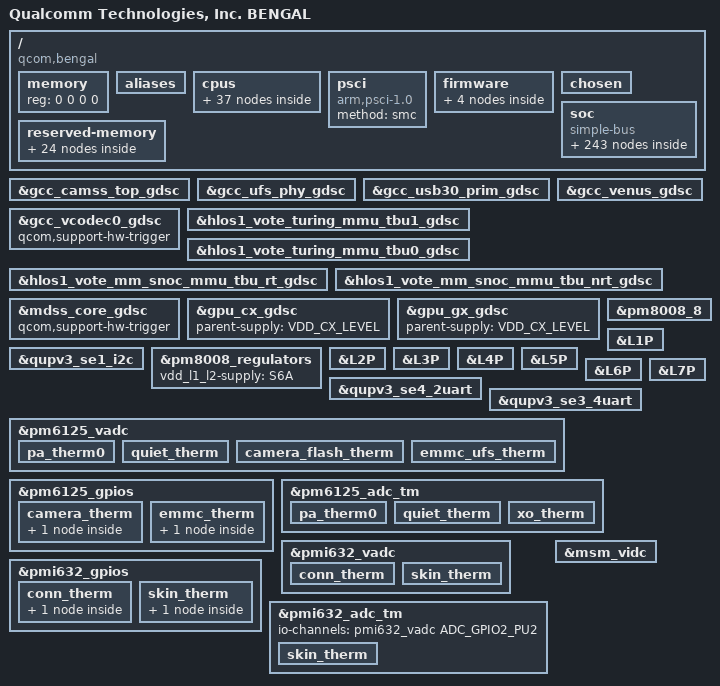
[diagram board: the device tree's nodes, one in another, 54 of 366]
#include <dt-bindings/interrupt-controller/arm-gic.h>
#include <dt-bindings/clock/qcom,rpmcc.h>
#include <dt-bindings/clock/qcom,dispcc-bengal.h>
#include <dt-bindings/clock/qcom,gcc-bengal.h>
#include <dt-bindings/clock/qcom,gpucc-bengal.h>
#include <dt-bindings/spmi/spmi.h>
#include <dt-bindings/regulator/qcom,rpmh-regulator-levels.h>
#include <dt-bindings/msm/msm-bus-ids.h>

#define MHZ_TO_MBPS(mhz, w) ((mhz * 1000000 * w) / (1024 * 1024))
#define BW_OPP_ENTRY(mhz, w) opp-mhz {opp-hz = /bits/ 64 <MHZ_TO_MBPS(mhz, w)>;}

#define BW_OPP_ENTRY_DDR(mhz, w, ddrtype) opp-mhz {\
				opp-hz = /bits/ 64 <MHZ_TO_MBPS(mhz, w)>;\
				opp-supported-hw = <ddrtype>;}

#define DDR_TYPE_LPDDR3		5
#define DDR_TYPE_LPDDR4X	7

/ {
	model = "Qualcomm Technologies, Inc. BENGAL";
	compatible = "qcom,bengal";
	qcom,msm-id = <417 0x10000>, <444 0x10000>;
	interrupt-parent = <&wakegic>;

	#address-cells = <2>;
	#size-cells = <2>;
	memory { device_type = "memory"; reg = <0 0 0 0>; };

	aliases {
		sdhc1 = &sdhc_1; /* SDC1 eMMC slot */
		sdhc2 = &sdhc_2; /* SDC2 SD Card slot */
		swr0 = &swr0;
		swr1 = &swr1;
		ufshc1 = &ufshc_mem; /* Embedded UFS slot */
	};

	cpus {
		#address-cells = <2>;
		#size-cells = <0>;

		CPU0: cpu@0 {
			device_type = "cpu";
			compatible = "arm,armv8";
			reg = <0x0 0x0>;
			capacity-dmips-mhz = <1024>;
			dynamic-power-coefficient = <100>;
			enable-method = "psci";
			d-cache-size = <0x8000>;
			i-cache-size = <0x8000>;
			next-level-cache = <&L2_0>;
			qcom,freq-domain = <&cpufreq_hw 0 7>;
			qcom,lmh-dcvs = <&lmh_dcvs0>;
			#cooling-cells = <2>;
			L2_0: l2-cache {
				compatible = "arm,arch-cache";
				cache-level = <2>;
			};

			L1_I_0: l1-icache {
				compatible = "arm,arch-cache";
			};

			L1_D_0: l1-dcache {
				compatible = "arm,arch-cache";
			};
		};

		CPU1: cpu@1 {
			device_type = "cpu";
			compatible = "arm,armv8";
			reg = <0x0 0x1>;
			capacity-dmips-mhz = <1024>;
			dynamic-power-coefficient = <100>;
			enable-method = "psci";
			d-cache-size = <0x8000>;
			i-cache-size = <0x8000>;
			next-level-cache = <&L2_0>;
			qcom,freq-domain = <&cpufreq_hw 0 7>;
			qcom,lmh-dcvs = <&lmh_dcvs0>;

			L1_I_1: l1-icache {
				compatible = "arm,arch-cache";
			};

			L1_D_1: l1-dcache {
				compatible = "arm,arch-cache";
			};
		};

		CPU2: cpu@2 {
			device_type = "cpu";
			compatible = "arm,armv8";
			reg = <0x0 0x2>;
			capacity-dmips-mhz = <1024>;
			dynamic-power-coefficient = <100>;
			enable-method = "psci";
			d-cache-size = <0x8000>;
			i-cache-size = <0x8000>;
			next-level-cache = <&L2_0>;
			qcom,freq-domain = <&cpufreq_hw 0 7>;
			qcom,lmh-dcvs = <&lmh_dcvs0>;

			L1_I_2: l1-icache {
				compatible = "arm,arch-cache";
			};

			L1_D_2: l1-dcache {
				compatible = "arm,arch-cache";
			};
		};

		CPU3: cpu@3 {
			device_type = "cpu";
			compatible = "arm,armv8";
			reg = <0x0 0x3>;
			capacity-dmips-mhz = <1024>;
			dynamic-power-coefficient = <100>;
			enable-method = "psci";
			d-cache-size = <0x8000>;
			i-cache-size = <0x8000>;
			next-level-cache = <&L2_0>;
			qcom,freq-domain = <&cpufreq_hw 0 7>;
			qcom,lmh-dcvs = <&lmh_dcvs0>;

			L1_I_3: l1-icache {
				compatible = "arm,arch-cache";
			};

			L1_D_3: l1-dcache {
				compatible = "arm,arch-cache";
			};
		};

		CPU4: cpu@100 {
			device_type = "cpu";
			compatible = "arm,armv8";
			reg = <0x0 0x100>;
			enable-method = "psci";
			capacity-dmips-mhz = <1638>;
			dynamic-power-coefficient = <282>;
			d-cache-size = <0x10000>;
			i-cache-size = <0x10000>;
			next-level-cache = <&L2_1>;
			qcom,freq-domain = <&cpufreq_hw 1 7>;
			qcom,lmh-dcvs = <&lmh_dcvs1>;
			#cooling-cells = <2>;
			L2_1: l2-cache {
				compatible = "arm,arch-cache";
				cache-level = <2>;
			};

			L1_I_100: l1-icache {
				compatible = "arm,arch-cache";
			};

			L1_D_100: l1-dcache {
				compatible = "arm,arch-cache";
			};
		};

		CPU5: cpu@101 {
			device_type = "cpu";
			compatible = "arm,armv8";
			reg = <0x0 0x101>;
			capacity-dmips-mhz = <1638>;
			dynamic-power-coefficient = <282>;
			enable-method = "psci";
			d-cache-size = <0x10000>;
			i-cache-size = <0x10000>;
			next-level-cache = <&L2_1>;
			qcom,freq-domain = <&cpufreq_hw 1 7>;
			qcom,lmh-dcvs = <&lmh_dcvs1>;

			L1_I_101: l1-icache {
				compatible = "arm,arch-cache";
			};

			L1_D_101: l1-dcache {
				compatible = "arm,arch-cache";
			};
		};

		CPU6: cpu@102 {
			device_type = "cpu";
			compatible = "arm,armv8";
			reg = <0x0 0x102>;
			capacity-dmips-mhz = <1638>;
			dynamic-power-coefficient = <282>;
			enable-method = "psci";
			d-cache-size = <0x10000>;
			i-cache-size = <0x10000>;
			next-level-cache = <&L2_1>;
			qcom,freq-domain = <&cpufreq_hw 1 7>;
			qcom,lmh-dcvs = <&lmh_dcvs1>;

			L1_I_102: l1-icache {
				compatible = "arm,arch-cache";
			};

			L1_D_102: l1-dcache {
				compatible = "arm,arch-cache";
			};
		};

		CPU7: cpu@103 {
			device_type = "cpu";
			compatible = "arm,armv8";
			reg = <0x0 0x103>;
			capacity-dmips-mhz = <1638>;
			dynamic-power-coefficient = <282>;
			enable-method = "psci";
			d-cache-size = <0x10000>;
			i-cache-size = <0x10000>;
			next-level-cache = <&L2_1>;
			qcom,freq-domain = <&cpufreq_hw 1 7>;
			qcom,lmh-dcvs = <&lmh_dcvs1>;

			L1_I_103: l1-icache {
				compatible = "arm,arch-cache";
			};

			L1_D_103: l1-dcache {
				compatible = "arm,arch-cache";
			};
		};

		cpu-map {
			cluster0 {
				core0 {
					cpu = <&CPU0>;
				};

				core1 {
					cpu = <&CPU1>;
				};

				core2 {
					cpu = <&CPU2>;
				};

				core3 {
					cpu = <&CPU3>;
				};
			};

			cluster1 {
				core0 {
					cpu = <&CPU4>;
				};

				core1 {
					cpu = <&CPU5>;
				};

				core2 {
					cpu = <&CPU6>;
				};

				core3 {
					cpu = <&CPU7>;
				};
			};
		};
	};

	psci {
		compatible = "arm,psci-1.0";
		method = "smc";
	};

	firmware: firmware {
		android {
			compatible = "android,firmware";
			vbmeta {
				compatible="android,vbmeta";
				parts = "vbmeta,boot,system,vendor,dtbo";
			};

			fstab {
				compatible = "android,fstab";
				vendor {
					compatible = "android,vendor";
					dev = "/dev/block/platform/soc/4744000.sdhci/by-name/vendor";
					type = "ext4";
					mnt_flags = "ro,barrier=1,discard";
					fsmgr_flags = "wait,slotselect,avb";
					status = "ok";
				};
			};
		};
	};

	reserved-memory {
		#address-cells = <2>;
		#size-cells = <2>;
		ranges;

		hyp_region: hyp_region@45700000 {
			compatible = "removed-dma-pool";
			no-map;
			reg = <0x0 0x45700000 0x0 0x600000>;
		};

		xbl_aop_mem: xbl_aop_mem@45e00000 {
			compatible = "removed-dma-pool";
			no-map;
			reg = <0x0 0x45e00000 0x0 0x140000>;
		};

		sec_apps_mem: sec_apps_region@45fff000 {
			compatible = "removed-dma-pool";
			no-map;
			reg = <0x0 0x45fff000 0x0 0x1000>;
		};

		smem_region: smem@46000000 {
			compatible = "removed-dma-pool";
			no-map;
			reg = <0x0 0x46000000 0x0 0x200000>;
		};

		removed_region: removed_region@46200000 {
			compatible = "removed-dma-pool";
			no-map;
			reg = <0x0 0x46200000 0x0 0x3900000>;
		};

		pil_modem_mem: modem_region@4ab00000 {
			compatible = "removed-dma-pool";
			no-map;
			reg = <0x0 0x4ab00000 0x0 0x7300000>;
		};

		pil_video_mem: pil_video_region@51e00000 {
			compatible = "removed-dma-pool";
			no-map;
			reg = <0x0 0x51e00000 0x0 0x500000>;
		};

		wlan_msa_mem: wlan_msa_region@52300000 {
			compatible = "removed-dma-pool";
			no-map;
			reg = <0x0 0x52300000 0x0 0x200000>;
		};

		pil_cdsp_mem: cdsp_regions@52500000 {
			compatible = "removed-dma-pool";
			no-map;
			reg = <0x0 0x52500000 0x0 0x1e00000>;
		};

		pil_adsp_mem: pil_adsp_region@54300000 {
			compatible = "removed-dma-pool";
			no-map;
			reg = <0x0 0x54300000 0x0 0x1e00000>;
		};

		pil_ipa_fw_mem: ips_fw_region@56100000 {
			compatible = "removed-dma-pool";
			no-map;
			reg = <0x0 0x56100000 0x0 0x10000>;
		};

		pil_ipa_gsi_mem: ipa_gsi_region@56110000 {
			compatible = "removed-dma-pool";
			no-map;
			reg = <0x0 0x56110000 0x0 0x5000>;
		};

		pil_gpu_mem: gpu_region@56115000 {
			compatible = "removed-dma-pool";
			no-map;
			reg = <0x0 0x56115000 0x0 0x2000>;
		};

		user_contig_mem: user_contig_region {
			compatible = "shared-dma-pool";
			alloc-ranges = <0x0 0x00000000 0x0 0xffffffff>;
			reusable;
			alignment = <0x0 0x400000>;
			size = <0x0 0x1000000>;
		};

		qseecom_mem: qseecom_region {
			compatible = "shared-dma-pool";
			alloc-ranges = <0x0 0x00000000 0x0 0xffffffff>;
			reusable;
			alignment = <0x0 0x400000>;
			size = <0x0 0x1400000>;
		};

		qseecom_ta_mem: qseecom_ta_region {
			compatible = "shared-dma-pool";
			alloc-ranges = <0x0 0x00000000 0x0 0xffffffff>;
			reusable;
			alignment = <0x0 0x400000>;
			size = <0x0 0x1000000>;
		};

		cdsp_sec_mem: cdsp_sec_regions@5f800000 {
			compatible = "removed-dma-pool";
			no-map;
			reg = <0x0 0x5f800000 0x0 0x1e00000>;
		};

		secure_display_memory: secure_display_region {
			compatible = "shared-dma-pool";
			alloc-ranges = <0 0x00000000 0 0xffffffff>;
			reusable;
			alignment = <0 0x400000>;
			size = <0 0x5c00000>;
		};

		cont_splash_memory: cont_splash_region@5c000000 {
			reg = <0x0 0x5c000000 0x0 0x00f00000>;
			label = "cont_splash_region";
		};

		disp_rdump_memory: disp_rdump_region@5c000000 {
			reg = <0x0 0x5c000000 0x0 0x01000000>;
			label = "disp_rdump_region";
		};

		dfps_data_memory: dfps_data_region@5cf00000 {
			reg = <0x0 0x5cf00000 0x0 0x0100000>;
			label = "dfps_data_region";
		};

		adsp_mem: adsp_region {
			compatible = "shared-dma-pool";
			alloc-ranges = <0 0x00000000 0 0xffffffff>;
			reusable;
			alignment = <0 0x400000>;
			size = <0 0x800000>;
		};

		dump_mem: mem_dump_region {
			compatible = "shared-dma-pool";
			reusable;
			size = <0 0x800000>;
		};

		/* global autoconfigured region for contiguous allocations */
		linux,cma {
			compatible = "shared-dma-pool";
			alloc-ranges = <0x0 0x00000000 0x0 0xffffffff>;
			reusable;
			alignment = <0x0 0x400000>;
			size = <0x0 0x2000000>;
			linux,cma-default;
		};
	};

	chosen {
		bootargs = "rcupdate.rcu_expedited=1 rcu_nocbs=0-7";
	};

	soc: soc { };
};

&soc {
	#address-cells = <1>;
	#size-cells = <1>;
	ranges = <0 0 0 0xffffffff>;
	compatible = "simple-bus";

	intc: interrupt-controller@f200000 {
		compatible = "arm,gic-v3";
		#interrupt-cells = <3>;
		interrupt-controller;
		interrupt-parent = <&intc>;
		#redistributor-regions = <1>;
		redistributor-stride = <0x0 0x20000>;
		reg = <0xf200000 0x10000>,     /* GICD */
		      <0xf300000 0x100000>;    /* GICR * 8 */
		interrupts = <1 9 4>;
	};

	jtag_mm0: jtagmm@9040000 {
		compatible = "qcom,jtagv8-mm";
		reg = <0x9040000 0x1000>;
		reg-names = "etm-base";

		clocks = <&rpmcc RPM_SMD_QDSS_CLK>;
		clock-names = "core_clk";

		qcom,coresight-jtagmm-cpu = <&CPU0>;
	};

	jtag_mm1: jtagmm@9140000 {
		compatible = "qcom,jtagv8-mm";
		reg = <0x9140000 0x1000>;
		reg-names = "etm-base";

		clocks = <&rpmcc RPM_SMD_QDSS_CLK>;
		clock-names = "core_clk";

		qcom,coresight-jtagmm-cpu = <&CPU1>;
	};

	jtag_mm2: jtagmm@9240000 {
		compatible = "qcom,jtagv8-mm";
		reg = <0x9240000 0x1000>;
		reg-names = "etm-base";

		clocks = <&rpmcc RPM_SMD_QDSS_CLK>;
		clock-names = "core_clk";

		qcom,coresight-jtagmm-cpu = <&CPU2>;
	};

	jtag_mm3: jtagmm@9340000 {
		compatible = "qcom,jtagv8-mm";
		reg = <0x9340000 0x1000>;
		reg-names = "etm-base";

		clocks = <&rpmcc RPM_SMD_QDSS_CLK>;
		clock-names = "core_clk";

		qcom,coresight-jtagmm-cpu = <&CPU3>;
	};

	jtag_mm4: jtagmm@9440000 {
		compatible = "qcom,jtagv8-mm";
		reg = <0x9440000 0x1000>;
		reg-names = "etm-base";

		clocks = <&rpmcc RPM_SMD_QDSS_CLK>;
		clock-names = "core_clk";

		qcom,coresight-jtagmm-cpu = <&CPU4>;
	};

	jtag_mm5: jtagmm@9540000 {
		compatible = "qcom,jtagv8-mm";
		reg = <0x9540000 0x1000>;
		reg-names = "etm-base";

		clocks = <&rpmcc RPM_SMD_QDSS_CLK>;
		clock-names = "core_clk";

		qcom,coresight-jtagmm-cpu = <&CPU5>;
	};

	jtag_mm6: jtagmm@9640000 {
		compatible = "qcom,jtagv8-mm";
		reg = <0x9640000 0x1000>;
		reg-names = "etm-base";

		clocks = <&rpmcc RPM_SMD_QDSS_CLK>;
		clock-names = "core_clk";

		qcom,coresight-jtagmm-cpu = <&CPU6>;
	};

	jtag_mm7: jtagmm@9740000 {
		compatible = "qcom,jtagv8-mm";
		reg = <0x9740000 0x1000>;
		reg-names = "etm-base";

		clocks = <&rpmcc RPM_SMD_QDSS_CLK>;
		clock-names = "core_clk";

		qcom,coresight-jtagmm-cpu = <&CPU7>;
	};

	qcom,memshare {
		compatible = "qcom,memshare";

		qcom,client_1 {
			compatible = "qcom,memshare-peripheral";
			qcom,peripheral-size = <0x0>;
			qcom,client-id = <0>;
			qcom,allocate-boot-time;
			label = "modem";
		};

		qcom,client_2 {
			compatible = "qcom,memshare-peripheral";
			qcom,peripheral-size = <0x0>;
			qcom,client-id = <2>;
			label = "modem";
		};

		mem_client_3_size: qcom,client_3 {
			compatible = "qcom,memshare-peripheral";
			qcom,peripheral-size = <0x500000>;
			qcom,client-id = <1>;
			qcom,allocate-on-request;
			label = "modem";
		};
	};

	slim_aud: slim@a5c0000 {
		cell-index = <1>;
		compatible = "qcom,slim-ngd";
		reg = <0xa5c0000 0x2c000>,
			<0xa584000 0x20000>, <0xa66e000 0x2000>;
		reg-names = "slimbus_physical",
			"slimbus_bam_physical", "slimbus_lpass_mem";
		interrupts = <GIC_SPI 283 IRQ_TYPE_LEVEL_HIGH>,
				<GIC_SPI 284 IRQ_TYPE_LEVEL_HIGH>;
		interrupt-names = "slimbus_irq", "slimbus_bam_irq";
		qcom,apps-ch-pipes = <0x0>;
		qcom,ea-pc = <0x360>;
		status = "ok";

		/* Slimbus Slave DT for WCN3990 */
		btfmslim_codec: wcn3990 {
			compatible = "qcom,btfmslim_slave";
			elemental-addr = [00 01 20 02 17 02];
			qcom,btfm-slim-ifd = "btfmslim_slave_ifd";
			qcom,btfm-slim-ifd-elemental-addr = [00 00 20 02 17 02];
		};
	};

	wakegic: wake-gic {
		compatible = "qcom,mpm-gic-bengal", "qcom,mpm-gic";
		interrupts-extended = <&wakegic GIC_SPI 197
						IRQ_TYPE_EDGE_RISING>;
		reg = <0x45f01b8 0x1000>,
			<0xf011008 0x4>;  /* MSM_APCS_GCC_BASE 4K */
		reg-names = "vmpm", "ipc";
		qcom,num-mpm-irqs = <96>;
		interrupt-controller;
		interrupt-parent = <&intc>;
		#interrupt-cells = <3>;
	};

	wakegpio: wake-gpio {
		compatible = "qcom,mpm-gpio";
		interrupt-controller;
		interrupt-parent = <&intc>;
		#interrupt-cells = <2>;
	};

	bluetooth: bt_wcn3990 {
		compatible = "qca,wcn3990";
		qca,bt-vdd-io-supply =   <&L9A>;  /* IO */
		qca,bt-vdd-core-supply = <&L17A>; /* RFA */
		qca,bt-vdd-pa-supply =   <&L23A>; /* CH0 */
		qca,bt-vdd-xtal-supply = <&L16A>; /* XO */

		qca,bt-vdd-io-voltage-level = <1700000 1900000>;
		qca,bt-vdd-core-voltage-level = <1304000 1304000>;
		qca,bt-vdd-pa-voltage-level = <3000000 3312000>;
		qca,bt-vdd-xtal-voltage-level = <1700000 1900000>;

		qca,bt-vdd-io-current-level = <1>; /* LPM/PFM */
		qca,bt-vdd-core-current-level = <1>; /* LPM/PFM */
		qca,bt-vdd-pa-current-level = <1>; /* LPM/PFM */
		qca,bt-vdd-xtal-current-level = <1>; /* LPM/PFM */
	};

	timer {
		compatible = "arm,armv8-timer";
		interrupts = <1 1 0xf08>,
			     <1 2 0xf08>,
			     <1 3 0xf08>,
			     <1 0 0xf08>;
		clock-frequency = <19200000>;
	};

	dcc: dcc_v2@1be2000 {
		compatible = "qcom,dcc-v2";
		reg = <0x1be2000 0x1000>,
			<0x1bee000 0x2000>;
		reg-names = "dcc-base", "dcc-ram-base";
		dcc-ram-offset = <0x2000>;
	};

	timer@f120000 {
		#address-cells = <1>;
		#size-cells = <1>;
		ranges;
		compatible = "arm,armv7-timer-mem";
		reg = <0xf120000 0x1000>;
		clock-frequency = <19200000>;

		frame@f121000 {
			frame-number = <0>;
			interrupts = <0 8 0x4>,
				     <0 7 0x4>;
			reg = <0xf121000 0x1000>,
			      <0xf122000 0x1000>;
		};

		frame@f123000 {
			frame-number = <1>;
			interrupts = <0 9 0x4>;
			reg = <0xf123000 0x1000>;
			status = "disabled";
		};

		frame@f124000 {
			frame-number = <2>;
			interrupts = <0 10 0x4>;
			reg = <0xf124000 0x1000>;
			status = "disabled";
		};

		frame@f125000 {
			frame-number = <3>;
			interrupts = <0 11 0x4>;
			reg = <0xf125000 0x1000>;
			status = "disabled";
		};

		frame@f126000 {
			frame-number = <4>;
			interrupts = <0 12 0x4>;
			reg = <0xf126000 0x1000>;
			status = "disabled";
		};

		frame@f127000 {
			frame-number = <5>;
			interrupts = <0 13 0x4>;
			reg = <0xf127000 0x1000>;
			status = "disabled";
		};

		frame@f128000 {
			frame-number = <6>;
			interrupts = <0 14 0x4>;
			reg = <0xf128000 0x1000>;
			status = "disabled";
		};
	};

	arm64_cpu_erp {
		compatible = "arm,arm64-cpu-erp";
		interrupt-names = "pri-dbe-irq",
				  "sec-dbe-irq",
				  "pri-ext-irq",
				  "sec-ext-irq";
		interrupts = <0 43 4>,
			     <0 44 4>,
			     <0 41 4>,
			     <0 42 4>;
		poll-delay-ms = <5000>;
	};

	l2cache_pmu {
		#address-cells = <1>;
		#size-cells = <1>;
		compatible = "qcom,l2cache-pmu";
		ranges;

		cluster0@f111000 {
			cluster-id = <0>;
			interrupts = <GIC_SPI 57 IRQ_TYPE_LEVEL_HIGH>;
			reg = <0xf111000 0x1000>;
		};

		cluster1@f011000 {
			cluster-id = <1>;
			interrupts = <GIC_SPI 58 IRQ_TYPE_LEVEL_HIGH>;
			reg = <0xf011000 0x1000>;
		};
	};

	qcom,msm-imem@c125000 {
		compatible = "qcom,msm-imem";
		reg = <0xc125000 0x1000>;
		ranges = <0x0 0xc125000 0x1000>;
		#address-cells = <1>;
		#size-cells = <1>;

		mem_dump_table@10 {
			compatible = "qcom,msm-imem-mem_dump_table";
			reg = <0x10 0x8>;
		};

		restart_reason@65c {
			compatible = "qcom,msm-imem-restart_reason";
			reg = <0x65c 0x4>;
		};

		dload_type@1c {
			compatible = "qcom,msm-imem-dload-type";
			reg = <0x1c 0x4>;
		};

		boot_stats@6b0 {
			compatible = "qcom,msm-imem-boot_stats";
			reg = <0x6b0 0x20>;
		};

		kaslr_offset@6d0 {
			compatible = "qcom,msm-imem-kaslr_offset";
			reg = <0x6d0 0xc>;
		};

		pil@94c {
			compatible = "qcom,msm-imem-pil";
			reg = <0x94c 0xc8>;
		};

		diag_dload@c8 {
			compatible = "qcom,msm-imem-diag-dload";
			reg = <0xc8 0xc8>;
		};
	};

	restart@440b000 {
		compatible = "qcom,pshold";
		reg = <0x440b000 0x4>,
		      <0x03d3000 0x4>;
		reg-names = "pshold-base", "tcsr-boot-misc-detect";
	};

	qcom_seecom: qseecom@47900000 {
		compatible = "qcom,qseecom";
		reg = <0x47900000 0x2200000>;
		reg-names = "secapp-region";
		memory-region = <&qseecom_mem>;
		qcom,hlos-num-ce-hw-instances = <1>;
		qcom,hlos-ce-hw-instance = <0>;
		qcom,qsee-ce-hw-instance = <0>;
		qcom,disk-encrypt-pipe-pair = <2>;
		qcom,support-fde;
		qcom,fde-key-size;
		qcom,appsbl-qseecom-support;
		qcom,commonlib64-loaded-by-uefi;
		qcom,msm-bus,name = "qseecom-noc";
		qcom,msm-bus,num-cases = <4>;
		qcom,msm-bus,num-paths = <1>;
		qcom,msm-bus,vectors-KBps =
			<MSM_BUS_MASTER_CRYPTO_CORE0
			MSM_BUS_SLAVE_FIRST 0 0>,
			<MSM_BUS_MASTER_CRYPTO_CORE0
			MSM_BUS_SLAVE_FIRST 200000 400000>,
			<MSM_BUS_MASTER_CRYPTO_CORE0
			MSM_BUS_SLAVE_FIRST 300000 800000>,
			<MSM_BUS_MASTER_CRYPTO_CORE0
			MSM_BUS_SLAVE_FIRST 400000 1000000>;
		clock-names =
			"core_clk_src", "core_clk",
			"iface_clk", "bus_clk";
		clocks =
			<&rpmcc QSEECOM_CE1_CLK>,
			<&rpmcc QSEECOM_CE1_CLK>,
			<&rpmcc QSEECOM_CE1_CLK>,
			<&rpmcc QSEECOM_CE1_CLK>;
		qcom,ce-opp-freq = <192000000>;
		qcom,qsee-reentrancy-support = <2>;
	};

	qcom_smcinvoke: smcinvoke@47900000 {
		compatible = "qcom,smcinvoke";
		reg = <0x47900000 0x2200000>;
		reg-names = "secapp-region";
	};

	qcom_rng: qrng@1b53000 {
		compatible = "qcom,msm-rng";
		reg = <0x1b53000 0x1000>;
		qcom,msm-rng-iface-clk;
		qcom,no-qrng-config;
		qcom,msm-bus,name = "msm-rng-noc";
		qcom,msm-bus,num-cases = <2>;
		qcom,msm-bus,num-paths = <1>;
		qcom,msm-bus,vectors-KBps =
			<MSM_BUS_MASTER_AMPSS_M0
			MSM_BUS_SLAVE_PRNG 0 0>,    /* No vote */
			<MSM_BUS_MASTER_AMPSS_M0
			MSM_BUS_SLAVE_PRNG 0 300000>;  /* 75 MHz */
		clocks = <&gcc GCC_PRNG_AHB_CLK>;
		clock-names = "iface_clk";
	};

	qcom_tzlog: tz-log@c125720 {
		compatible = "qcom,tz-log";
		reg = <0xc125720 0x3000>;
		qcom,hyplog-enabled;
		hyplog-address-offset = <0x410>;
		hyplog-size-offset = <0x414>;
	};

	qcom_cedev: qcedev@1b20000 {
		compatible = "qcom,qcedev";
		reg = <0x1b20000 0x20000>,
			<0x1b04000 0x24000>;
		reg-names = "crypto-base","crypto-bam-base";
		interrupts = <GIC_SPI 247 IRQ_TYPE_LEVEL_HIGH>;
		qcom,bam-pipe-pair = <3>;
		qcom,ce-hw-instance = <0>;
		qcom,ce-device = <0>;
		qcom,ce-hw-shared;
		qcom,bam-ee = <0>;
		qcom,msm-bus,name = "qcedev-noc";
		qcom,msm-bus,num-cases = <2>;
		qcom,msm-bus,num-paths = <1>;
		qcom,msm-bus,vectors-KBps =
				<MSM_BUS_MASTER_CRYPTO_CORE0
				MSM_BUS_SLAVE_FIRST 0 0>,
				<MSM_BUS_MASTER_CRYPTO_CORE0
				MSM_BUS_SLAVE_FIRST 393600 393600>;
		clock-names =
			"core_clk_src", "core_clk",
			"iface_clk", "bus_clk";
		clocks =
			<&rpmcc QCEDEV_CE1_CLK>,
			<&rpmcc QCEDEV_CE1_CLK>,
			<&rpmcc QCEDEV_CE1_CLK>,
			<&rpmcc QCEDEV_CE1_CLK>;
		qcom,ce-opp-freq = <192000000>;
		qcom,smmu-s1-enable;
		iommus = <&apps_smmu 0x0086 0x0011>,
			 <&apps_smmu 0x0096 0x0011>;
		qcom,iommu-dma = "atomic";

		qcom_cedev_ns_cb {
			compatible = "qcom,qcedev,context-bank";
			label = "ns_context";
			iommus = <&apps_smmu 0x92 0>,
				<&apps_smmu 0x98 0x1>,
				<&apps_smmu 0x9F 0>;
		};

		qcom_cedev_s_cb {
			compatible = "qcom,qcedev,context-bank";
			label = "secure_context";
			iommus = <&apps_smmu 0x93 0>,
				<&apps_smmu 0x9C 0x1>,
				<&apps_smmu 0x9E 0>;
			qcom,iommu-vmid = <0x9>; /* VMID_CP_BITSTREAM */
			qcom,secure-context-bank;
		};
	};

	qcom_crypto: qcrypto@1b20000 {
		compatible = "qcom,qcrypto";
		reg = <0x1b20000 0x20000>,
			<0x1b04000 0x24000>;
		reg-names = "crypto-base","crypto-bam-base";
		interrupts = <GIC_SPI 247 IRQ_TYPE_LEVEL_HIGH>;
		qcom,bam-pipe-pair = <2>;
		qcom,ce-hw-instance = <0>;
		qcom,ce-device = <0>;
		qcom,bam-ee = <0>;
		qcom,ce-hw-shared;
		qcom,clk-mgmt-sus-res;
		qcom,msm-bus,name = "qcrypto-noc";
		qcom,msm-bus,num-cases = <2>;
		qcom,msm-bus,num-paths = <1>;
		qcom,msm-bus,vectors-KBps =
			<MSM_BUS_MASTER_CRYPTO_CORE0
			MSM_BUS_SLAVE_FIRST
			0 0>,
			<MSM_BUS_MASTER_CRYPTO_CORE0
			MSM_BUS_SLAVE_FIRST
			393600 393600>;
		clock-names =
			"core_clk_src", "core_clk",
			"iface_clk", "bus_clk";
		clocks =
			<&rpmcc QCRYPTO_CE1_CLK>,
			<&rpmcc QCRYPTO_CE1_CLK>,
			<&rpmcc QCRYPTO_CE1_CLK>,
			<&rpmcc QCRYPTO_CE1_CLK>;
		qcom,use-sw-aes-cbc-ecb-ctr-algo;
		qcom,use-sw-aes-xts-algo;
		qcom,use-sw-aes-ccm-algo;
		qcom,use-sw-ahash-algo;
		qcom,use-sw-aead-algo;
		qcom,use-sw-hmac-algo;
		qcom,smmu-s1-enable;
		iommus = <&apps_smmu 0x0084 0x0011>,
			<&apps_smmu 0x0094 0x0011>;
		qcom,iommu-dma = "atomic";
	};

	qcom,mpm2-sleep-counter@4403000 {
		compatible = "qcom,mpm2-sleep-counter";
		reg = <0x4403000 0x1000>;
		clock-frequency = <32768>;
	};

	qcom,msm-rtb {
		compatible = "qcom,msm-rtb";
		qcom,rtb-size = <0x100000>;
	};

	cpu_pmu: cpu-pmu {
		compatible = "arm,armv8-pmuv3";
		qcom,irq-is-percpu;
		interrupts = <1 6 4>;
	};

	eud: qcom,msm-eud@1610000 {
		compatible = "qcom,msm-eud";
		interrupt-names = "eud_irq";
		interrupts = <GIC_SPI 189 IRQ_TYPE_LEVEL_HIGH>;
		reg = <0x1610000 0x2000>,
		      <0x1612000 0x1000>,
		      <0x3E5018 0x4>;
		reg-names = "eud_base", "eud_mode_mgr2",
				"eud_tcsr_check_reg";
		qcom,secure-eud-en;
		qcom,eud-tcsr-check-enable;
		status = "ok";
	};

	qcom,msm-gladiator-v2@f100000 {
		compatible = "qcom,msm-gladiator-v2";
		reg = <0xf100000 0xdc00>;
		reg-names = "gladiator_base";
		interrupts = <GIC_SPI 22 IRQ_TYPE_LEVEL_HIGH>;
		clock-names = "atb_clk";
		clocks = <&rpmcc RPM_QDSS_CLK>;
	};

	wdog: qcom,wdt@f017000 {
		compatible = "qcom,msm-watchdog";
		reg = <0xf017000 0x1000>;
		reg-names = "wdt-base";
		interrupts = <GIC_SPI 3 IRQ_TYPE_EDGE_RISING>,
			     <GIC_SPI 4 IRQ_TYPE_LEVEL_HIGH>;
		qcom,bark-time = <11000>;
		qcom,pet-time = <9360>;
		qcom,ipi-ping;
		qcom,wakeup-enable;
	};

	rpm_bus: qcom,rpm-smd {
		compatible = "qcom,rpm-smd";
		rpm-channel-name = "rpm_requests";
		interrupts = <GIC_SPI 194 IRQ_TYPE_EDGE_RISING>;
		rpm-channel-type = <15>; /* SMD_APPS_RPM */
	};

	qcom,chd_silver {
		compatible = "qcom,core-hang-detect";
		label = "silver";
		qcom,threshold-arr = <0x0f1880b0 0x0f1980b0
				      0x0f1a80b0 0x0f1b80b0>;
		qcom,config-arr = <0x0f1880b8 0x0f1980b8
				   0x0f1a80b8 0x0f1b80b8>;
	};

	qcom,chd_gold {
		compatible = "qcom,core-hang-detect";
		label = "gold";
		qcom,threshold-arr = <0x0f0880b0 0x0f0980b0
				      0x0f0a80b0 0x0f0b80b0>;
		qcom,config-arr = <0x0f0880b8 0x0f0980b8
				   0x0f0a80b8 0x0f0b80b8>;
	};

	qcom,ghd {
		compatible = "qcom,gladiator-hang-detect";
		qcom,threshold-arr = <0x0f1d141c 0x0f1d1420
				      0x0f1d1424 0x0f1d1428
				      0x0f1d142c 0x0f1d1430>;
		qcom,config-reg = <0x0f1d1434>;
	};

	qcom,lpass@ab00000 {
		compatible = "qcom,pil-tz-generic";
		reg = <0xab00000 0x00100>;

		vdd_lpi_cx-supply = <&L3A_LEVEL>;
		qcom,proxy-reg-names = "vdd_lpi_cx", "vdd_lpi_mx";
		qcom,vdd_lpi_cx-uV-uA = <RPMH_REGULATOR_LEVEL_TURBO 0>;
		vdd_lpi_mx-supply = <&L2A_LEVEL>;
		qcom,vdd_lpi_mx-uV-uA = <RPMH_REGULATOR_LEVEL_TURBO 0>;

		clocks = <&rpmcc CXO_SMD_PIL_LPASS_CLK>;
		clock-names = "xo";
		qcom,proxy-clock-names = "xo";
		qcom,mas-crypto = <&mas_crypto_c0>;

		qcom,pas-id = <1>;
		qcom,proxy-timeout-ms = <10000>;
		qcom,smem-id = <423>;
		qcom,minidump-id = <5>;
		qcom,sysmon-id = <1>;
		qcom,ssctl-instance-id = <0x14>;
		qcom,firmware-name = "adsp";
		memory-region = <&pil_adsp_mem>;
		qcom,complete-ramdump;

		/* Inputs from lpass */
		interrupts-extended = <&intc 0 282 1>,
				      <&adsp_smp2p_in 0 0>,
				      <&adsp_smp2p_in 2 0>,
				      <&adsp_smp2p_in 1 0>,
				      <&adsp_smp2p_in 3 0>;

		interrupt-names = "qcom,wdog",
				  "qcom,err-fatal",
				  "qcom,proxy-unvote",
				  "qcom,err-ready",
				  "qcom,stop-ack";

		/* Outputs to lpass */
		qcom,smem-states = <&adsp_smp2p_out 0>;
		qcom,smem-state-names = "qcom,force-stop";
	};

	qcom,turing@b300000 {
		compatible = "qcom,pil-tz-generic";
		reg = <0xb300000 0x100000>;

		vdd_cx-supply = <&VDD_CX_LEVEL>;
		qcom,proxy-reg-names = "vdd_cx";
		qcom,vdd_cx-uV-uA = <RPMH_REGULATOR_LEVEL_TURBO 100000>;

		clocks = <&rpmcc CXO_SMD_PIL_CDSP_CLK>;
		clock-names = "xo";
		qcom,proxy-clock-names = "xo";
		qcom,mas-crypto = <&mas_crypto_c0>;

		qcom,pas-id = <18>;
		qcom,proxy-timeout-ms = <10000>;
		qcom,smem-id = <601>;
		qcom,minidump-id = <7>;
		qcom,sysmon-id = <7>;
		qcom,ssctl-instance-id = <0x17>;
		qcom,firmware-name = "cdsp";
		memory-region = <&pil_cdsp_mem>;
		qcom,complete-ramdump;

		/* Inputs from turing */
		interrupts-extended = <&intc 0 265 1>,
				      <&cdsp_smp2p_in 0 0>,
				      <&cdsp_smp2p_in 2 0>,
				      <&cdsp_smp2p_in 1 0>,
				      <&cdsp_smp2p_in 3 0>;

		interrupt-names = "qcom,wdog",
				  "qcom,err-fatal",
				  "qcom,proxy-unvote",
				  "qcom,err-ready",
				  "qcom,stop-ack";

		/* Outputs to turing */
		qcom,smem-states = <&cdsp_smp2p_out 0>;
		qcom,smem-state-names = "qcom,force-stop";
	};

	mem_dump {
		compatible = "qcom,mem-dump";
		memory-region = <&dump_mem>;

		c0_context {
			qcom,dump-size = <0x800>;
			qcom,dump-id = <0x0>;
		};

		c1_context {
			qcom,dump-size = <0x800>;
			qcom,dump-id = <0x1>;
		};

		c2_context {
			qcom,dump-size = <0x800>;
			qcom,dump-id = <0x2>;
		};

		c3_context {
			qcom,dump-size = <0x800>;
			qcom,dump-id = <0x3>;
		};

		c100_context {
			qcom,dump-size = <0x800>;
			qcom,dump-id = <0x4>;
		};

		c101_context {
			qcom,dump-size = <0x800>;
			qcom,dump-id = <0x5>;
		};

		c102_context {
			qcom,dump-size = <0x800>;
			qcom,dump-id = <0x6>;
		};

		c103_context {
			qcom,dump-size = <0x800>;
			qcom,dump-id = <0x7>;
		};

		c0_scandump {
			qcom,dump-size = <0x40000>;
			qcom,dump-id = <0x130>;
		};

		c1_scandump {
			qcom,dump-size = <0x40000>;
			qcom,dump-id = <0x131>;
		};

		c2_scandump {
			qcom,dump-size = <0x40000>;
			qcom,dump-id = <0x132>;
		};

		c3_scandump {
			qcom,dump-size = <0x40000>;
			qcom,dump-id = <0x133>;
		};

		c100_scandump {
			qcom,dump-size = <0x40000>;
			qcom,dump-id = <0x134>;
		};

		c101_scandump {
			qcom,dump-size = <0x40000>;
			qcom,dump-id = <0x135>;
		};

		c102_scandump {
			qcom,dump-size = <0x40000>;
			qcom,dump-id = <0x136>;
		};

		c103_scandump {
			qcom,dump-size = <0x40000>;
			qcom,dump-id = <0x137>;
		};

		l1_icache0 {
			qcom,dump-size = <0x9040>;
			qcom,dump-id = <0x60>;
		};

		l1_icache1 {
			qcom,dump-size = <0x9040>;
			qcom,dump-id = <0x61>;
		};

		l1_icache2 {
			qcom,dump-size = <0x9040>;
			qcom,dump-id = <0x62>;
		};

		l1_icache3 {
			qcom,dump-size = <0x9040>;
			qcom,dump-id = <0x63>;
		};

		l1_icache100 {
			qcom,dump-size = <0x12000>;
			qcom,dump-id = <0x64>;
		};

		l1_icache101 {
			qcom,dump-size = <0x12000>;
			qcom,dump-id = <0x65>;
		};

		l1_icache102 {
			qcom,dump-size = <0x12000>;
			qcom,dump-id = <0x66>;
		};

		l1_icache103 {
			qcom,dump-size = <0x12000>;
			qcom,dump-id = <0x67>;
		};

		l1_dcache0 {
			qcom,dump-size = <0x9040>;
			qcom,dump-id = <0x80>;
		};

		l1_dcache1 {
			qcom,dump-size = <0x9040>;
			qcom,dump-id = <0x81>;
		};

		l1_dcache2 {
			qcom,dump-size = <0x9040>;
			qcom,dump-id = <0x82>;
		};

		l1_dcache3 {
			qcom,dump-size = <0x9040>;
			qcom,dump-id = <0x83>;
		};

		l1_dcache100 {
			qcom,dump-size = <0x12000>;
			qcom,dump-id = <0x84>;
		};

		l1_dcache101 {
			qcom,dump-size = <0x12000>;
			qcom,dump-id = <0x85>;
		};

		l1_dcache102 {
			qcom,dump-size = <0x12000>;
			qcom,dump-id = <0x86>;
		};

		l1_dcache103 {
			qcom,dump-size = <0x12000>;
			qcom,dump-id = <0x87>;
		};

		l2_tlb0 {
			qcom,dump-size = <0x2000>;
			qcom,dump-id = <0x120>;
		};

		l2_tlb1 {
			qcom,dump-size = <0x2000>;
			qcom,dump-id = <0x121>;
		};

		l2_tlb2 {
			qcom,dump-size = <0x2000>;
			qcom,dump-id = <0x122>;
		};

		l2_tlb3 {
			qcom,dump-size = <0x2000>;
			qcom,dump-id = <0x123>;
		};

		l2_tlb100 {
			qcom,dump-size = <0x4800>;
			qcom,dump-id = <0x124>;
		};

		l2_tlb101 {
			qcom,dump-size = <0x4800>;
			qcom,dump-id = <0x125>;
		};

		l2_tlb102 {
			qcom,dump-size = <0x4800>;
			qcom,dump-id = <0x126>;
		};

		l2_tlb103 {
			qcom,dump-size = <0x4800>;
			qcom,dump-id = <0x127>;
		};

		rpm_sw {
			qcom,dump-size = <0x28000>;
			qcom,dump-id = <0xea>;
		};

		pmic {
			qcom,dump-size = <0x10000>;
			qcom,dump-id = <0xe4>;
		};

		fcm {
			qcom,dump-size = <0x8400>;
			qcom,dump-id = <0xee>;
		};

		tmc_etf {
			qcom,dump-size = <0x8000>;
			qcom,dump-id = <0xf0>;
		};

		etr_reg {
			qcom,dump-size = <0x1000>;
			qcom,dump-id = <0x100>;
		};

		etf_reg {
			qcom,dump-size = <0x1000>;
			qcom,dump-id = <0x101>;
		};

		misc_data {
			qcom,dump-size = <0x1000>;
			qcom,dump-id = <0xe8>;
		};
	};

	sdcc1_ice: sdcc1ice@4748000 {
		compatible = "qcom,ice";
		reg = <0x4748000 0x8000>;
		qcom,enable-ice-clk;
		clock-names = "ice_core_clk_src", "ice_core_clk",
				"bus_clk", "iface_clk";
		clocks = <&gcc GCC_SDCC1_ICE_CORE_CLK_SRC>,
			<&gcc GCC_SDCC1_ICE_CORE_CLK>,
			<&gcc GCC_SDCC1_AHB_CLK>,
			<&gcc GCC_SDCC1_APPS_CLK>;
		qcom,op-freq-hz = <300000000>, <0>, <0>, <0>;
		qcom,msm-bus,name = "sdcc_ice_noc";
		qcom,msm-bus,num-cases = <2>;
		qcom,msm-bus,num-paths = <1>;
		qcom,msm-bus,vectors-KBps =
				<MSM_BUS_MASTER_AMPSS_M0
				MSM_BUS_SLAVE_SDCC_1 0 0>,    /* No vote */
				<MSM_BUS_MASTER_AMPSS_M0
				MSM_BUS_SLAVE_SDCC_1 1000 0>;
				/* Max. bandwidth */
		qcom,bus-vector-names = "MIN",
					"MAX";
		qcom,instance-type = "sdcc";
	};

	sdhc_1: sdhci@4744000 {
		compatible = "qcom,sdhci-msm-v5", "qcom,sdhci-msm-cqe";
		reg = <0x4744000 0x1000>, <0x4745000 0x1000>;
		reg-names = "hc_mem", "cqhci_mem";

		interrupts = <GIC_SPI 348 IRQ_TYPE_LEVEL_HIGH>,
				<GIC_SPI 352 IRQ_TYPE_LEVEL_HIGH>;
		interrupt-names = "hc_irq", "pwr_irq";
		sdhc-msm-crypto = <&sdcc1_ice>;

		qcom,bus-width = <8>;
		qcom,large-address-bus;

		qcom,clk-rates = <400000 20000000 25000000 50000000 100000000
						192000000 384000000>;
		qcom,bus-speed-mode = "HS400_1p8v", "HS200_1p8v", "DDR_1p8v";

		qcom,devfreq,freq-table = <50000000 200000000>;

		qcom,scaling-lower-bus-speed-mode = "DDR52";

		qcom,msm-bus,name = "sdhc1";
		qcom,msm-bus,num-cases = <9>;
		qcom,msm-bus,num-paths = <2>;
		qcom,msm-bus,vectors-KBps =
			/* No vote */
			<78 512 0 0>, <1 606 0 0>,
			/* 400 KB/s*/
			<78 512 1046 1600>,
			<1 606 1600 1600>,
			/* 20 MB/s */
			<78 512 20480 80000>,
			<1 606 80000 80000>,
			/* 25 MB/s */
			<78 512 25600 250000>,
			<1 606 50000 133320>,
			/* 50 MB/s */
			<78 512 51200 250000>,
			<1 606 65000 133320>,
			/* 100 MB/s */
			<78 512 102400 250000>,
			<1 606 65000 133320>,
			/* 200 MB/s */
			<78 512 204800 800000>,
			<1 606 200000 300000>,
			/* 400 MB/s */
			<78 512 204800 800000>,
			<1 606 200000 300000>,
			/* Max. bandwidth */
			<78 512 1338562 4096000>,
			<1 606 1338562 4096000>;
		qcom,bus-bw-vectors-bps = <0 400000 20000000 25000000 50000000
			100750000 200000000 400000000 4294967295>;

		/* PM QoS */
		qcom,pm-qos-irq-type = "affine_irq";
		qcom,pm-qos-irq-latency = <26 26>;
		qcom,pm-qos-cpu-groups = <0x0f 0xf0>;
		qcom,pm-qos-cmdq-latency-us = <26 26>, <26 26>;
		qcom,pm-qos-legacy-latency-us = <26 26>, <26 26>;

		clocks = <&gcc GCC_SDCC1_AHB_CLK>,
			<&gcc GCC_SDCC1_APPS_CLK>,
			<&gcc GCC_SDCC1_ICE_CORE_CLK>;
		clock-names = "iface_clk", "core_clk", "ice_core_clk";

		qcom,ice-clk-rates = <300000000 100000000>;

		/* DLL HSR settings. Refer go/hsr - <Target> DLL settings */
		qcom,dll-hsr-list = <0x000f642c 0x0 0x0 0x00010800 0x80040868>;

		qcom,nonremovable;
		status = "disabled";
	};

	sdhc_2: sdhci@4784000 {
		compatible = "qcom,sdhci-msm-v5";
		reg = <0x4784000 0x1000>;
		reg-names = "hc_mem";

		interrupts = <GIC_SPI 350 IRQ_TYPE_LEVEL_HIGH>,
				<GIC_SPI 353 IRQ_TYPE_LEVEL_HIGH>;
		interrupt-names = "hc_irq", "pwr_irq";

		qcom,bus-width = <4>;
		qcom,large-address-bus;

		qcom,clk-rates = <400000 20000000 25000000
				50000000 100000000 202000000>;
		qcom,bus-speed-mode = "SDR12", "SDR25", "SDR50", "DDR50",
				      "SDR104";

		qcom,devfreq,freq-table = <50000000 202000000>;

		qcom,msm-bus,name = "sdhc2";
		qcom,msm-bus,num-cases = <8>;
		qcom,msm-bus,num-paths = <2>;
		qcom,msm-bus,vectors-KBps =
			/* No vote */
			<81 512 0 0>, <1 608 0 0>,
			/* 400 KB/s*/
			<81 512 1046 3200>,
			<1 608 1600 1600>,
			/* 20 MB/s */
			<81 512 52286 250000>,
			<1 608 80000 133320>,
			/* 25 MB/s */
			<81 512 65360 250000>,
			<1 608 100000 133320>,
			/* 50 MB/s */
			<81 512 130718 250000>,
			<1 608 133320 133320>,
			/* 100 MB/s */
			<81 512 261438 250000>,
			<1 608 150000 133320>,
			/* 200 MB/s */
			<81 512 261438 800000>,
			<1 608 300000 300000>,
			/* Max. bandwidth */
			<81 512 1338562 4096000>,
			<1 608 1338562 4096000>;
		qcom,bus-bw-vectors-bps = <0 400000 20000000 25000000 50000000
			100750000 200000000 4294967295>;

		/* PM QoS */
		qcom,pm-qos-irq-type = "affine_irq";
		qcom,pm-qos-irq-latency = <26 26>;
		qcom,pm-qos-cpu-groups = <0x0f 0xf0>;
		qcom,pm-qos-legacy-latency-us = <26 26>, <26 26>;


		clocks = <&gcc GCC_SDCC2_AHB_CLK>,
			<&gcc GCC_SDCC2_APPS_CLK>;
		clock-names = "iface_clk", "core_clk";

		/* DLL HSR settings. Refer go/hsr - <Target> DLL settings */
		qcom,dll-hsr-list = <0x0007642c 0x0 0x0 0x00010800 0x80040868>;

		status = "disabled";
	};

	ufs_ice: ufsice@4810000 {
		compatible = "qcom,ice";
		reg = <0x4810000 0x8000>;
		qcom,enable-ice-clk;
		clock-names = "ufs_core_clk", "bus_clk",
				"iface_clk", "ice_core_clk";
		clocks = <&gcc GCC_UFS_PHY_AXI_CLK>,
			<&gcc GCC_UFS_CLKREF_CLK>,
			<&gcc GCC_UFS_PHY_AHB_CLK>,
			<&gcc GCC_UFS_PHY_ICE_CORE_CLK>;
		qcom,op-freq-hz = <0>, <0>, <0>, <300000000>;
		vdd-hba-supply = <&gcc_ufs_phy_gdsc>;
		qcom,msm-bus,name = "ufs_ice_noc";
		qcom,msm-bus,num-cases = <2>;
		qcom,msm-bus,num-paths = <1>;
		qcom,msm-bus,vectors-KBps =
				<MSM_BUS_MASTER_AMPSS_M0
				 MSM_BUS_SLAVE_UFS_MEM_CFG 0 0>, /*No vote*/
				<MSM_BUS_MASTER_AMPSS_M0
				 MSM_BUS_SLAVE_UFS_MEM_CFG 1000 0>;
				 /* Max. bandwidth */
		qcom,bus-vector-names = "MIN",
					"MAX";
		qcom,instance-type = "ufs";
	};

	ufsphy_mem: ufsphy_mem@4807000 {
		reg = <0x4807000 0xdb8>; /* PHY regs */
		reg-names = "phy_mem";
		#phy-cells = <0>;

		lanes-per-direction = <1>;

		clock-names = "ref_clk_src",
			"ref_clk",
			"ref_aux_clk";
		clocks = <&rpmcc RPM_SMD_XO_CLK_SRC>,
			<&gcc GCC_UFS_CLKREF_CLK>,
			<&gcc GCC_UFS_PHY_PHY_AUX_CLK>;

		status = "disabled";
	};

	ufshc_mem: ufshc@4804000 {
		compatible = "qcom,ufshc";
		reg = <0x4804000 0x3000>;
		interrupts = <GIC_SPI 356 IRQ_TYPE_LEVEL_HIGH>;
		phys = <&ufsphy_mem>;
		phy-names = "ufsphy";
		ufs-qcom-crypto = <&ufs_ice>;

		lanes-per-direction = <1>;
		dev-ref-clk-freq = <0>; /* 19.2 MHz */
		spm-level = <5>;

		clock-names =
			"core_clk",
			"bus_aggr_clk",
			"iface_clk",
			"core_clk_unipro",
			"core_clk_ice",
			"ref_clk",
			"tx_lane0_sync_clk",
			"rx_lane0_sync_clk";
		clocks =
			<&gcc GCC_UFS_PHY_AXI_CLK>,
			<&gcc GCC_SYS_NOC_UFS_PHY_AXI_CLK>,
			<&gcc GCC_UFS_PHY_AHB_CLK>,
			<&gcc GCC_UFS_PHY_UNIPRO_CORE_CLK>,
			<&gcc GCC_UFS_PHY_ICE_CORE_CLK>,
			<&rpmcc RPM_SMD_XO_CLK_SRC>,
			<&gcc GCC_UFS_PHY_TX_SYMBOL_0_CLK>,
			<&gcc GCC_UFS_PHY_RX_SYMBOL_0_CLK>;
		freq-table-hz =
			<50000000 200000000>,
			<0 0>,
			<0 0>,
			<37500000 150000000>,
			<75000000 300000000>,
			<0 0>,
			<0 0>,
			<0 0>;

		qcom,msm-bus,name = "ufshc_mem";
		qcom,msm-bus,num-cases = <12>;
		qcom,msm-bus,num-paths = <2>;
		qcom,msm-bus,vectors-KBps =
		/*
		 * During HS G3 UFS runs at nominal voltage corner, vote
		 * higher bandwidth to push other buses in the data path
		 * to run at nominal to achieve max throughput.
		 * 4GBps pushes BIMC to run at nominal.
		 * 200MBps pushes CNOC to run at nominal.
		 * Vote for half of this bandwidth for HS G3 1-lane.
		 * For max bandwidth, vote high enough to push the buses
		 * to run in turbo voltage corner.
		 */
		<123 512 0 0>, <1 757 0 0>,          /* No vote */
		<123 512 922 0>, <1 757 1000 0>,     /* PWM G1 */
		<123 512 1844 0>, <1 757 1000 0>,    /* PWM G2 */
		<123 512 3688 0>, <1 757 1000 0>,    /* PWM G3 */
		<123 512 7376 0>, <1 757 1000 0>,    /* PWM G4 */
		<123 512 127796 0>, <1 757 1000 0>,  /* HS G1 RA */
		<123 512 255591 0>, <1 757 1000 0>,  /* HS G2 RA */
		<123 512 2097152 0>, <1 757 102400 0>,  /* HS G3 RA */
		<123 512 149422 0>, <1 757 1000 0>,  /* HS G1 RB */
		<123 512 298189 0>, <1 757 1000 0>,  /* HS G2 RB */
		<123 512 2097152 0>, <1 757 102400 0>,  /* HS G3 RB */
		<123 512 7643136 0>, <1 757 307200 0>; /* Max. bandwidth */

		qcom,bus-vector-names = "MIN",
		"PWM_G1_L1", "PWM_G2_L1", "PWM_G3_L1", "PWM_G4_L1",
		"HS_RA_G1_L1", "HS_RA_G2_L1", "HS_RA_G3_L1",
		"HS_RB_G1_L1", "HS_RB_G2_L1", "HS_RB_G3_L1",
		"MAX";

		/* PM QoS */
		qcom,pm-qos-cpu-groups = <0x0f 0xf0>;
		qcom,pm-qos-cpu-group-latency-us = <26 26>;
		qcom,pm-qos-default-cpu = <0>;

		pinctrl-names = "dev-reset-assert", "dev-reset-deassert";
		pinctrl-0 = <&ufs_dev_reset_assert>;
		pinctrl-1 = <&ufs_dev_reset_deassert>;

		resets = <&gcc GCC_UFS_PHY_BCR>;
		reset-names = "core_reset";
		non-removable;

		status = "disabled";
	};

	thermal_zones: thermal-zones {};

	tsens0:tsens@c222000 {
		compatible = "qcom,tsens24xx";
		reg = <0x04410000  0x8>,
		      <0x04411000  0x1ff>;
		reg-names = "tsens_srot_physical",
			     "tsens_tm_physical";
		interrupts = <0 275 0>, <0 190 0>;
		interrupt-names = "tsens-upper-lower", "tsens-critical";
		#thermal-sensor-cells = <1>;
	};

	clocks {
		xo_board: xo_board {
			compatible = "fixed-clock";
			clock-frequency = <19200000>;
			clock-output-names = "xo_board";
			#clock-cells = <0>;
		};

		sleep_clk: sleep_clk {
			compatible = "fixed-clock";
			clock-frequency = <32764>;
			clock-output-names = "sleep_clk";
			#clock-cells = <0>;
		};
	};

	rpmcc: qcom,rpmcc {
		compatible = "qcom,rpmcc-bengal";
		#clock-cells = <1>;
	};

	qcom,rmtfs_sharedmem@0 {
		compatible = "qcom,sharedmem-uio";
		reg = <0x0 0x200000>;
		reg-names = "rmtfs";
		qcom,client-id = <0x00000001>;
		qcom,guard-memory;
		qcom,vm-nav-path;
	};

	gcc: qcom,gcc@1400000 {
		compatible = "qcom,bengal-gcc", "syscon";
		reg = <0x1400000 0x1f0000>;
		reg-names = "cc_base";
		vdd_cx-supply = <&VDD_CX_LEVEL>;
		vdd_cx_ao-supply = <&VDD_CX_LEVEL_AO>;
		vdd_mx-supply = <&VDD_MX_LEVEL>;
		#clock-cells = <1>;
		#reset-cells = <1>;
	};

	dispcc: qcom,dispcc@5f00000 {
		compatible = "qcom,bengal-dispcc", "syscon";
		reg = <0x05f00000 0x20000>;
		reg-names = "cc_base";
		clock-names = "cfg_ahb_clk";
		clocks = <&gcc GCC_DISP_AHB_CLK>;
		vdd_cx-supply = <&VDD_CX_LEVEL>;
		#clock-cells = <1>;
		#reset-cells = <1>;
	};

	gpucc: qcom,gpucc@5990000 {
		compatible = "qcom,bengal-gpucc", "syscon";
		reg = <0x5990000 0x9000>;
		reg-names = "cc_base";
		vdd_cx-supply = <&VDD_CX_LEVEL>;
		qcom,gpu_cc_gx_gfx3d_clk_src-opp-handle = <&msm_gpu>;
		#clock-cells = <1>;
		#reset-cells = <1>;
	};

	mccc_debug: syscon@447d200 {
		compatible = "syscon";
		reg = <0x447d200 0x100>;
	};

	cpucc_debug: syscon@f11101c {
		compatible = "syscon";
		reg = <0xf11101c 0x4>;
	};

	debugcc: qcom,cc-debug {
		compatible = "qcom,bengal-debugcc";
		qcom,gcc = <&gcc>;
		qcom,dispcc = <&dispcc>;
		qcom,gpucc = <&gpucc>;
		qcom,mccc = <&mccc_debug>;
		qcom,cpucc = <&cpucc_debug>;
		clock-names = "xo_clk_src";
		clocks = <&rpmcc RPM_SMD_XO_CLK_SRC>;
		#clock-cells = <1>;
	};

	cpufreq_hw: qcom,cpufreq-hw {
		compatible = "qcom,cpufreq-hw";
		reg = <0xf521000 0x1000>, <0xf523000 0x1000>;
		reg-names = "freq-domain0", "freq-domain1";
		clocks = <&rpmcc RPM_SMD_XO_CLK_SRC>, <&gcc GPLL0>;
		clock-names = "xo", "alternate";
		qcom,no-accumulative-counter;
		qcom,max-lut-entries = <12>;
		#freq-domain-cells = <2>;
	};

	tcsr_mutex_block: syscon@00340000 {
		compatible = "syscon";
		reg = <0x340000 0x20000>;
	};

	tcsr_mutex: hwlock {
		compatible = "qcom,tcsr-mutex";
		syscon = <&tcsr_mutex_block 0 0x1000>;
		#hwlock-cells = <1>;
	};

	smem: qcom,smem {
		compatible = "qcom,smem";
		memory-region = <&smem_region>;
		hwlocks = <&tcsr_mutex 3>;
	};

	rpm_msg_ram: memory@045f0000 {
			compatible = "qcom,rpm-msg-ram";
			reg = <0x45f0000 0x7000>;
	};

	apcs_glb: mailbox@0f111000 {
		compatible = "qcom,bengal-apcs-hmss-global";
		reg = <0xF111000 0x1000>;

		#mbox-cells = <1>;
	};

	qcom,msm-cdsp-loader {
		compatible = "qcom,cdsp-loader";
		qcom,proc-img-to-load = "cdsp";
	};

	qcom,msm-adsprpc-mem {
		compatible = "qcom,msm-adsprpc-mem-region";
		memory-region = <&adsp_mem>;
		restrict-access;
	};

	qcom,msm_fastrpc {
		compatible = "qcom,msm-fastrpc-compute";
		qcom,rpc-latency-us = <611>;
		qcom,adsp-remoteheap-vmid = <22 37>;
		qcom,fastrpc-adsp-audio-pdr;
		qcom,fastrpc-adsp-sensors-pdr;

		qcom,msm_fastrpc_compute_cb1 {
			compatible = "qcom,msm-fastrpc-compute-cb";
			label = "cdsprpc-smd";
			iommus = <&apps_smmu 0x0C01 0x0>;
		};

		qcom,msm_fastrpc_compute_cb2 {
			compatible = "qcom,msm-fastrpc-compute-cb";
			label = "cdsprpc-smd";
			iommus = <&apps_smmu 0x0C02 0x0>;
		};

		qcom,msm_fastrpc_compute_cb3 {
			compatible = "qcom,msm-fastrpc-compute-cb";
			label = "cdsprpc-smd";
			iommus = <&apps_smmu 0x0C03 0x0>;
		};

		qcom,msm_fastrpc_compute_cb4 {
			compatible = "qcom,msm-fastrpc-compute-cb";
			label = "cdsprpc-smd";
			iommus = <&apps_smmu 0x0C04 0x0>;
		};

		qcom,msm_fastrpc_compute_cb5 {
			compatible = "qcom,msm-fastrpc-compute-cb";
			label = "cdsprpc-smd";
			iommus = <&apps_smmu 0x0C05 0x0>;
		};

		qcom,msm_fastrpc_compute_cb6 {
			compatible = "qcom,msm-fastrpc-compute-cb";
			label = "cdsprpc-smd";
			iommus = <&apps_smmu 0x0C06 0x0>;
		};

		qcom,msm_fastrpc_compute_cb9 {
			compatible = "qcom,msm-fastrpc-compute-cb";
			label = "cdsprpc-smd";
			qcom,secure-context-bank;
			iommus = <&apps_smmu 0x0C09 0x0>;
		};

		qcom,msm_fastrpc_compute_cb10 {
			compatible = "qcom,msm-fastrpc-compute-cb";
			label = "adsprpc-smd";
			iommus = <&apps_smmu 0x01C3 0x0>;
		};

		qcom,msm_fastrpc_compute_cb11 {
			compatible = "qcom,msm-fastrpc-compute-cb";
			label = "adsprpc-smd";
			iommus = <&apps_smmu 0x01C4 0x0>;
		};

		qcom,msm_fastrpc_compute_cb12 {
			compatible = "qcom,msm-fastrpc-compute-cb";
			label = "adsprpc-smd";
			iommus = <&apps_smmu 0x01C5 0x0>;
		};

		qcom,msm_fastrpc_compute_cb13 {
			compatible = "qcom,msm-fastrpc-compute-cb";
			label = "adsprpc-smd";
			iommus = <&apps_smmu 0x01C6 0x0>;
		};

		qcom,msm_fastrpc_compute_cb14 {
			compatible = "qcom,msm-fastrpc-compute-cb";
			label = "adsprpc-smd";
			iommus = <&apps_smmu 0x01C7 0x0>;
		};

	};

	rpm-glink {
		compatible = "qcom,glink-rpm";
		interrupts = <GIC_SPI 194 IRQ_TYPE_EDGE_RISING>;
		qcom,rpm-msg-ram = <&rpm_msg_ram>;
		mboxes = <&apcs_glb 0>;

		qcom,rpm_glink_ssr {
			qcom,glink-channels = "glink_ssr";
			qcom,notify-edges = <&glink_modem>,
					    <&glink_adsp>,
					    <&glink_cdsp>;
		};

	};

	qcom,glink {
		compatible = "qcom,glink";
		#address-cells = <1>;
		#size-cells = <1>;
		ranges;

		glink_modem: modem {
			qcom,remote-pid = <1>;
			transport = "smem";
			mboxes = <&apcs_glb 12>;
			mbox-names = "mpss_smem";
			interrupts = <GIC_SPI 68 IRQ_TYPE_EDGE_RISING>;

			label = "modem";
			qcom,glink-label = "mpss";

			qcom,modem_qrtr {
				qcom,glink-channels = "IPCRTR";
				qcom,low-latency;
				qcom,intents = <0x800  5
						0x2000 3
						0x4400 2>;
			};

			qcom,msm_fastrpc_rpmsg {
				compatible = "qcom,msm-fastrpc-rpmsg";
				qcom,glink-channels = "fastrpcglink-apps-dsp";
				qcom,intents = <0x64 64>;
			};

			qcom,modem_ds {
				qcom,glink-channels = "DS";
				qcom,intents = <0x4000 2>;
			};

			qcom,modem_glink_ssr {
				qcom,glink-channels = "glink_ssr";
				qcom,notify-edges = <&glink_adsp>,
						    <&glink_cdsp>;
			};
		};

		glink_adsp: adsp {
			qcom,remote-pid = <2>;
			transport = "smem";
			mboxes = <&apcs_glb 8>;
			mbox-names = "adsp_smem";
			interrupts = <GIC_SPI 277 IRQ_TYPE_EDGE_RISING>;

			label = "adsp";
			qcom,glink-label = "lpass";

			qcom,adsp_qrtr {
				qcom,glink-channels = "IPCRTR";
				qcom,low-latency;
				qcom,intents = <0x800  5
						0x2000 3
						0x4400 2>;
			};

			qcom,apr_tal_rpmsg {
				qcom,glink-channels = "apr_audio_svc";
				qcom,intents = <0x200 20>;
			};

			qcom,msm_fastrpc_rpmsg {
				compatible = "qcom,msm-fastrpc-rpmsg";
				qcom,glink-channels = "fastrpcglink-apps-dsp";
				qcom,intents = <0x64 64>;
			};

			qcom,adsp_glink_ssr {
				qcom,glink-channels = "glink_ssr";
				qcom,notify-edges = <&glink_modem>,
						    <&glink_cdsp>;
			};
		};

		glink_cdsp: cdsp {
			qcom,remote-pid = <5>;
			transport = "smem";
			mboxes = <&apcs_glb 28>;
			mbox-names = "cdsp_smem";
			interrupts = <GIC_SPI 261 IRQ_TYPE_EDGE_RISING>;

			label = "cdsp";
			qcom,glink-label = "cdsp";

			qcom,cdsp_qrtr {
				qcom,glink-channels = "IPCRTR";
				qcom,intents = <0x800  5
						0x2000 3
						0x4400 2>;
			};

			qcom,msm_fastrpc_rpmsg {
				compatible = "qcom,msm-fastrpc-rpmsg";
				qcom,glink-channels = "fastrpcglink-apps-dsp";
				qcom,intents = <0x64 64>;
			};

			qcom,msm_cdsprm_rpmsg {
				compatible = "qcom,msm-cdsprm-rpmsg";
				qcom,glink-channels = "cdsprmglink-apps-dsp";
				qcom,intents = <0x20 12>;

				msm_cdsp_rm: qcom,msm_cdsp_rm {
					compatible = "qcom,msm-cdsp-rm";
					qcom,qos-latency-us = <100>;
					qcom,qos-maxhold-ms = <20>;
				};
			};

			qcom,cdsp_glink_ssr {
				qcom,glink-channels = "glink_ssr";
				qcom,notify-edges = <&glink_modem>,
						    <&glink_adsp>;
			};
		};
	};

	qcom,glinkpkt {
		compatible = "qcom,glinkpkt";

		qcom,glinkpkt-at-mdm0 {
			qcom,glinkpkt-edge = "mpss";
			qcom,glinkpkt-ch-name = "DS";
			qcom,glinkpkt-dev-name = "at_mdm0";
		};

		qcom,glinkpkt-apr-apps2 {
			qcom,glinkpkt-edge = "adsp";
			qcom,glinkpkt-ch-name = "apr_apps2";
			qcom,glinkpkt-dev-name = "apr_apps2";
		};

		qcom,glinkpkt-data40-cntl {
			qcom,glinkpkt-edge = "mpss";
			qcom,glinkpkt-ch-name = "DATA40_CNTL";
			qcom,glinkpkt-dev-name = "smdcntl8";
		};

		qcom,glinkpkt-data1 {
			qcom,glinkpkt-edge = "mpss";
			qcom,glinkpkt-ch-name = "DATA1";
			qcom,glinkpkt-dev-name = "smd7";
		};

		qcom,glinkpkt-data4 {
			qcom,glinkpkt-edge = "mpss";
			qcom,glinkpkt-ch-name = "DATA4";
			qcom,glinkpkt-dev-name = "smd8";
		};

		qcom,glinkpkt-data11 {
			qcom,glinkpkt-edge = "mpss";
			qcom,glinkpkt-ch-name = "DATA11";
			qcom,glinkpkt-dev-name = "smd11";
		};
	};

	qcom,smp2p_sleepstate {
		compatible = "qcom,smp2p-sleepstate";
		qcom,smem-states = <&sleepstate_smp2p_out 0>;
		interrupt-parent = <&sleepstate_smp2p_in>;
		interrupts = <0 0>;
		interrupt-names = "smp2p-sleepstate-in";
	};

	qcom,smp2p-modem {
		compatible = "qcom,smp2p";
		qcom,smem = <435>, <428>;
		interrupts = <GIC_SPI 70 IRQ_TYPE_EDGE_RISING>;
		mboxes = <&apcs_glb 14>;
		qcom,local-pid = <0>;
		qcom,remote-pid = <1>;

		modem_smp2p_out: master-kernel {
			qcom,entry-name = "master-kernel";
			#qcom,smem-state-cells = <1>;
		};

		modem_smp2p_in: slave-kernel {
			qcom,entry-name = "slave-kernel";
			interrupt-controller;
			#interrupt-cells = <2>;
		};

		smp2p_ipa_1_out: qcom,smp2p-ipa-1-out {
			qcom,entry-name = "ipa";
			#qcom,smem-state-cells = <1>;
		};

		/* ipa - inbound entry from mss */
		smp2p_ipa_1_in: qcom,smp2p-ipa-1-in {
			qcom,entry-name = "ipa";
			interrupt-controller;
			#interrupt-cells = <2>;
		};

		smp2p_wlan_1_in: qcom,smp2p-wlan-1-in {
			qcom,entry-name = "wlan";
			interrupt-controller;
			#interrupt-cells = <2>;
		};

	};

	qcom,smp2p-adsp {
		compatible = "qcom,smp2p";
		qcom,smem = <443>, <429>;
		interrupts = <GIC_SPI 279 IRQ_TYPE_EDGE_RISING>;
		mboxes = <&apcs_glb 10>;
		qcom,local-pid = <0>;
		qcom,remote-pid = <2>;

		adsp_smp2p_out: master-kernel {
			qcom,entry-name = "master-kernel";
			#qcom,smem-state-cells = <1>;
		};

		adsp_smp2p_in: slave-kernel {
			qcom,entry-name = "slave-kernel";
			interrupt-controller;
			#interrupt-cells = <2>;
		};

		smp2p_rdbg2_out: qcom,smp2p-rdbg2-out {
			qcom,entry-name = "rdbg";
			#qcom,smem-state-cells = <1>;
		};

		smp2p_rdbg2_in: qcom,smp2p-rdbg2-in {
			qcom,entry-name = "rdbg";
			interrupt-controller;
			#interrupt-cells = <2>;
		};

		sleepstate_smp2p_out: sleepstate-out {
			qcom,entry-name = "sleepstate";
			#qcom,smem-state-cells = <1>;
		};

		sleepstate_smp2p_in: qcom,sleepstate-in {
			qcom,entry-name = "sleepstate_see";
			interrupt-controller;
			#interrupt-cells = <2>;
		};
	};

	qcom,smp2p-cdsp {
		compatible = "qcom,smp2p";
		qcom,smem = <94>, <432>;
		interrupts = <GIC_SPI 263 IRQ_TYPE_EDGE_RISING>;
		mboxes = <&apcs_glb 30>;
		qcom,local-pid = <0>;
		qcom,remote-pid = <5>;

		cdsp_smp2p_out: master-kernel {
			qcom,entry-name = "master-kernel";
			#qcom,smem-state-cells = <1>;
		};

		cdsp_smp2p_in: slave-kernel {
			qcom,entry-name = "slave-kernel";
			interrupt-controller;
			#interrupt-cells = <2>;
		};

		smp2p_rdbg5_out: qcom,smp2p-rdbg5-out {
			qcom,entry-name = "rdbg";
			#qcom,smem-state-cells = <1>;
		};

		smp2p_rdbg5_in: qcom,smp2p-rdbg5-in {
			qcom,entry-name = "rdbg";
			interrupt-controller;
			#interrupt-cells = <2>;
		};
	};

	qcom,sps {
		compatible = "qcom,msm-sps-4k";
		qcom,pipe-attr-ee;
	};

	qfprom: qfprom@1b40000 {
		compatible = "qcom,qfprom";
		reg = <0x1b40000 0x7000>;
		#address-cells = <1>;
		#size-cells = <1>;
		read-only;
		ranges;

		stm_debug_fuse: stm@20f0 {
			reg = <0x20f0 0x4>;
		};

		feat_conf5: feat_conf5@6018 {
			reg = <0x6018 0x4>;
		};

		adsp_variant: adsp_variant@6011 {
			reg = <0x6011 0x1>;
			bits = <3 1>;
		};

		gpu_speed_bin: gpu_speed_bin@6006 {
			reg = <0x6006 0x2>;
			bits = <5 8>;
		};

		gpu_gaming_bin: gpu_gaming_bin@602d {
			reg = <0x602d 0x1>;
			bits = <5 1>;
		};
	};

	spmi_bus: qcom,spmi@1c40000 {
		compatible = "qcom,spmi-pmic-arb";
		reg = <0x1c40000 0x1100>,
			<0x1e00000 0x2000000>,
			<0x3e00000 0x100000>,
			<0x3f00000 0xa0000>,
			<0x1c0a000 0x26000>;
		reg-names = "core", "chnls", "obsrvr", "intr", "cnfg";
		interrupt-names = "periph_irq";
		interrupts = <GIC_SPI 183 IRQ_TYPE_LEVEL_HIGH>;
		qcom,ee = <0>;
		qcom,channel = <0>;
		#address-cells = <1>;
		#size-cells = <1>;
		interrupt-controller;
		#interrupt-cells = <4>;
		cell-index = <0>;
	};

	icnss: qcom,icnss@C800000 {
		compatible = "qcom,icnss";
		reg = <0xC800000 0x800000>,
		      <0xb0000000 0x10000>;
		reg-names = "membase", "smmu_iova_ipa";
		iommus = <&apps_smmu 0x1A0 0x1>;
		interrupts = <GIC_SPI 358 IRQ_TYPE_LEVEL_HIGH /* CE0 */ >,
			     <GIC_SPI 359 IRQ_TYPE_LEVEL_HIGH /* CE1 */ >,
			     <GIC_SPI 360 IRQ_TYPE_LEVEL_HIGH /* CE2 */ >,
			     <GIC_SPI 361 IRQ_TYPE_LEVEL_HIGH /* CE3 */ >,
			     <GIC_SPI 362 IRQ_TYPE_LEVEL_HIGH /* CE4 */ >,
			     <GIC_SPI 363 IRQ_TYPE_LEVEL_HIGH /* CE5 */ >,
			     <GIC_SPI 364 IRQ_TYPE_LEVEL_HIGH /* CE6 */ >,
			     <GIC_SPI 365 IRQ_TYPE_LEVEL_HIGH /* CE7 */ >,
			     <GIC_SPI 366 IRQ_TYPE_LEVEL_HIGH /* CE8 */ >,
			     <GIC_SPI 367 IRQ_TYPE_LEVEL_HIGH /* CE9 */ >,
			     <GIC_SPI 368 IRQ_TYPE_LEVEL_HIGH /* CE10 */ >,
			     <GIC_SPI 369 IRQ_TYPE_LEVEL_HIGH /* CE11 */ >;
		qcom,iommu-dma = "bypass";
		qcom,wlan-msa-fixed-region = <&wlan_msa_mem>;
		qcom,iommu-dma-addr-pool = <0xa0000000 0x10000000>;
		vdd-cx-mx-supply = <&L8A>;
		vdd-1.8-xo-supply = <&L16A>;
		vdd-1.3-rfa-supply = <&L17A>;
		vdd-3.3-ch0-supply = <&L23A>;
		qcom,vdd-cx-mx-config = <0 0>;
		qcom,vdd-3.3-ch0-config = <3000000 3312000>;
		qcom,smp2p_map_wlan_1_in {
			interrupts-extended = <&smp2p_wlan_1_in 0 0>,
					      <&smp2p_wlan_1_in 1 0>;
			interrupt-names = "qcom,smp2p-force-fatal-error",
					  "qcom,smp2p-early-crash-ind";
		};
	};

	qcom,venus@5ab0000 {
		compatible = "qcom,pil-tz-generic";
		reg = <0x5ab0000 0x20000>;

		vdd-supply = <&gcc_venus_gdsc>;
		qcom,proxy-reg-names = "vdd";

		clocks =
			<&gcc GCC_VIDEO_XO_CLK>,
			<&gcc GCC_VIDEO_VENUS_CTL_CLK>,
			<&gcc GCC_VENUS_CTL_AXI_CLK>,
			<&gcc GCC_VENUS_AHB_CLK>,
			<&gcc GCC_VIDEO_AXI0_CLK>,
			<&gcc GCC_VIDEO_AHB_CLK>,
			<&gcc GCC_VIDEO_THROTTLE_CORE_CLK>;
		clock-names = "xo_clock", "core_clk", "bus_clk", "iface_clk", "video_bus0_clk", "video_iface_clk", "throttle_clk";
		qcom,proxy-clock-names = "xo_clock", "core_clk", "bus_clk", "iface_clk", "video_bus0_clk", "video_iface_clk", "throttle_clk";
		qcom,mas-crypto = <&mas_crypto_c0>;

		qcom,core-freq = <240000000>;
		qcom,ahb-freq = <240000000>;

		qcom,pas-id = <9>;
		qcom,msm-bus,name = "pil-venus";
		qcom,msm-bus,num-cases = <2>;
		qcom,msm-bus,num-paths = <1>;
		qcom,msm-bus,vectors-KBps =
			<63 512 0 0>,
			<63 512 0 304000>;
		qcom,proxy-timeout-ms = <100>;
		qcom,firmware-name = "venus";
		memory-region = <&pil_video_mem>;
	};

	cx_ipeak_lm: cx_ipeak@3ed000 {
		compatible = "qcom,cx-ipeak-v2";
		reg = <0x3ed000 0xe008>;
	};

	pil_modem: qcom,mss@6080000 {
		compatible = "qcom,pil-tz-generic";
		reg = <0x6080000 0x100>;

		clocks = <&rpmcc CXO_SMD_PIL_MSS_CLK>;
		clock-names = "xo";
		qcom,proxy-clock-names = "xo";
		qcom,mas-crypto = <&mas_crypto_c0>;

		vdd_cx-supply = <&VDD_CX_LEVEL>;
		qcom,vdd_cx-uV-uA = <RPMH_REGULATOR_LEVEL_TURBO 100000>;
		qcom,proxy-reg-names = "vdd_cx";

		qcom,firmware-name = "modem";
		memory-region = <&pil_modem_mem>;
		qcom,proxy-timeout-ms = <10000>;
		qcom,sysmon-id = <0>;
		qcom,ssctl-instance-id = <0x12>;
		qcom,pas-id = <4>;
		qcom,smem-id = <421>;
		qcom,minidump-id = <3>;
		qcom,aux-minidump-ids = <4>;
		qcom,complete-ramdump;

		/* Inputs from mss */
		interrupts-extended = <&intc 0 307 1>,
				<&modem_smp2p_in 0 0>,
				<&modem_smp2p_in 2 0>,
				<&modem_smp2p_in 1 0>,
				<&modem_smp2p_in 3 0>,
				<&modem_smp2p_in 7 0>;

		interrupt-names = "qcom,wdog",
				"qcom,err-fatal",
				"qcom,proxy-unvote",
				"qcom,err-ready",
				"qcom,stop-ack",
				"qcom,shutdown-ack";

		/* Outputs to mss */
		qcom,smem-states = <&modem_smp2p_out 0>;
		qcom,smem-state-names = "qcom,force-stop";
	};

	ddr_bw_opp_table: ddr-bw-opp-table {
		compatible = "operating-points-v2";
		BW_OPP_ENTRY_DDR( 200, 8, 0xA0); /* 1525 MB/s */
		BW_OPP_ENTRY_DDR( 300, 8, 0xA0); /* 2288 MB/s */
		BW_OPP_ENTRY_DDR( 451, 8, 0xA0); /* 3440 MB/s */
		BW_OPP_ENTRY_DDR( 547, 8, 0xA0); /* 4173 MB/s */
		BW_OPP_ENTRY_DDR( 681, 8, 0xA0); /* 5195 MB/s */
		BW_OPP_ENTRY_DDR( 768, 8, 0xA0); /* 5859 MB/s */
		BW_OPP_ENTRY_DDR( 931, 8, 0x20); /* 7102 MB/s */
		BW_OPP_ENTRY_DDR(1017, 8, 0x80); /* 7759 MB/s */
		BW_OPP_ENTRY_DDR(1353, 8, 0x80); /*10322 MB/s */
		BW_OPP_ENTRY_DDR(1555, 8, 0x80); /*11863 MB/s */
		BW_OPP_ENTRY_DDR(1804, 8, 0x80); /*13763 MB/s */
	};

	suspendable_ddr4_bw_opp_table: suspendable-ddr4-bw-opp-table {
		compatible = "operating-points-v2";
		BW_OPP_ENTRY_DDR(   0, 8, 0xA0); /*    0 MB/s */
		BW_OPP_ENTRY_DDR( 200, 8, 0xA0); /* 1525 MB/s */
		BW_OPP_ENTRY_DDR( 300, 8, 0xA0); /* 2288 MB/s */
		BW_OPP_ENTRY_DDR( 451, 8, 0xA0); /* 3440 MB/s */
		BW_OPP_ENTRY_DDR( 547, 8, 0xA0); /* 4173 MB/s */
		BW_OPP_ENTRY_DDR( 681, 8, 0xA0); /* 5195 MB/s */
		BW_OPP_ENTRY_DDR( 768, 8, 0xA0); /* 5859 MB/s */
		BW_OPP_ENTRY_DDR( 931, 8, 0x20); /* 7102 MB/s */
		BW_OPP_ENTRY_DDR(1017, 8, 0x80); /* 7759 MB/s */
		BW_OPP_ENTRY_DDR(1353, 8, 0x80); /*10322 MB/s */
		BW_OPP_ENTRY_DDR(1555, 8, 0x80); /*11863 MB/s */
		BW_OPP_ENTRY_DDR(1804, 8, 0x80); /*13763 MB/s */
	};

	cpu_cpu_ddr_bw: qcom,cpu-cpu-ddr-bw {
		compatible = "qcom,devbw-ddr";
		governor = "performance";
		qcom,src-dst-ports =
			<MSM_BUS_MASTER_AMPSS_M0 MSM_BUS_SLAVE_EBI_CH0>;
		qcom,active-only;
		operating-points-v2 = <&ddr_bw_opp_table>;
	};

	cpu_cpu_ddr_bwmon: qcom,cpu-cpu-ddr-bwmon@01b8e200 {
		compatible = "qcom,bimc-bwmon4";
		reg = <0x01b8e300 0x100>, <0x01b8e200 0x100>;
		reg-names = "base", "global_base";
		interrupts = <GIC_SPI 421 IRQ_TYPE_LEVEL_HIGH>;
		qcom,mport = <0>;
		qcom,hw-timer-hz = <19200000>;
		qcom,target-dev = <&cpu_cpu_ddr_bw>;
		qcom,count-unit = <0x10000>;
	};

	cpu0_cpu_ddr_latfloor: qcom,cpu0-cpu-ddr-latfloor {
		compatible = "qcom,devbw-ddr";
		governor = "performance";
		qcom,src-dst-ports =
			<MSM_BUS_MASTER_AMPSS_M0 MSM_BUS_SLAVE_EBI_CH0>;
		qcom,active-only;
		operating-points-v2 = <&ddr_bw_opp_table>;
	};

	cpu0_cpu_ddr_lat: qcom,cpu0-cpu-ddr-lat {
		compatible = "qcom,devbw-ddr";
		governor = "performance";
		qcom,src-dst-ports =
			<MSM_BUS_MASTER_AMPSS_M0 MSM_BUS_SLAVE_EBI_CH0>;
		qcom,active-only;
		operating-points-v2 = <&ddr_bw_opp_table>;
	};

	cpu0_memlat_cpugrp: qcom,cpu0-cpugrp {
		compatible = "qcom,arm-memlat-cpugrp";
		qcom,cpulist = <&CPU0 &CPU1 &CPU2 &CPU3>;

		cpu0_cpu_ddr_latmon: qcom,cpu0-cpu-ddr-latmon {
			compatible = "qcom,arm-memlat-mon";
			qcom,cpulist = <&CPU0 &CPU1 &CPU2 &CPU3>;
			qcom,target-dev = <&cpu0_cpu_ddr_lat>;
			qcom,cachemiss-ev = <0x17>;
			qcom,stall-cycle-ev = <0xE7>;
			ddr3-map {
				qcom,ddr-type = <DDR_TYPE_LPDDR3>;
				qcom,core-dev-table =
					<  864000 MHZ_TO_MBPS(200, 8) >,
					< 1305600 MHZ_TO_MBPS(451, 8) >,
					< 1804800 MHZ_TO_MBPS(768, 8) >;
			};

			ddr4-map {
				qcom,ddr-type = <DDR_TYPE_LPDDR4X>;
				qcom,core-dev-table =
					<  864000 MHZ_TO_MBPS( 300, 8) >,
					< 1305600 MHZ_TO_MBPS( 547, 8) >,
					< 1420000 MHZ_TO_MBPS( 768, 8) >,
					< 1804800 MHZ_TO_MBPS(1017, 8) >;
			};
		};

		cpu0_computemon: qcom,cpu0-computemon {
			compatible = "qcom,arm-compute-mon";
			qcom,cpulist = <&CPU0 &CPU1 &CPU2 &CPU3>;
			qcom,target-dev = <&cpu0_cpu_ddr_latfloor>;
			ddr3-map {
				qcom,ddr-type = <DDR_TYPE_LPDDR3>;
				qcom,core-dev-table =
					<  614400 MHZ_TO_MBPS( 200, 8) >,
					< 1305600 MHZ_TO_MBPS( 451, 8) >,
					< 1804800 MHZ_TO_MBPS( 768, 8) >;
			};

			ddr4-map {
				qcom,ddr-type = <DDR_TYPE_LPDDR4X>;
				qcom,core-dev-table =
					<  614400 MHZ_TO_MBPS( 300, 8) >,
					< 1017600 MHZ_TO_MBPS( 451, 8) >,
					< 1420000 MHZ_TO_MBPS( 547, 8) >,
					< 1804800 MHZ_TO_MBPS( 768, 8) >;
			};
		};
	};

	cpu4_cpu_ddr_lat: qcom,cpu4-cpu-ddr-lat {
		compatible = "qcom,devbw-ddr";
		governor = "performance";
		qcom,src-dst-ports =
			<MSM_BUS_MASTER_AMPSS_M0 MSM_BUS_SLAVE_EBI_CH0>;
		qcom,active-only;
		operating-points-v2 = <&ddr_bw_opp_table>;
	};

	cpu4_cpu_ddr_latfloor: qcom,cpu4-cpu-ddr-latfloor {
		compatible = "qcom,devbw-ddr";
		governor = "performance";
		qcom,src-dst-ports =
			<MSM_BUS_MASTER_AMPSS_M0 MSM_BUS_SLAVE_EBI_CH0>;
		qcom,active-only;
		operating-points-v2 = <&ddr_bw_opp_table>;
	};

	cpu4_memlat_cpugrp: qcom,cpu4-cpugrp {
		compatible = "qcom,arm-memlat-cpugrp";
		qcom,cpulist = <&CPU4 &CPU5 &CPU6 &CPU7>;

		cpu4_cpu_ddr_latmon: qcom,cpu4-cpu-ddr-latmon {
			compatible = "qcom,arm-memlat-mon";
			qcom,cpulist = <&CPU4 &CPU5 &CPU6 &CPU7>;
			qcom,target-dev = <&cpu4_cpu_ddr_lat>;
			qcom,cachemiss-ev = <0x17>;
			qcom,stall-cycle-ev = <0x24>;
			ddr3-map {
				qcom,ddr-type = <DDR_TYPE_LPDDR3>;
				qcom,core-dev-table =
					< 1056000 MHZ_TO_MBPS(200, 8) >,
					< 1401600 MHZ_TO_MBPS(451, 8) >,
					< 1804800 MHZ_TO_MBPS(768, 8) >,
					< 2016000 MHZ_TO_MBPS(931, 8) >;
			};

			ddr4-map {
				qcom,ddr-type = <DDR_TYPE_LPDDR4X>;
				qcom,core-dev-table =
					<  902400 MHZ_TO_MBPS( 451, 8) >,
					< 1401600 MHZ_TO_MBPS(1017, 8) >,
					< 1804800 MHZ_TO_MBPS(1555, 8) >,
					< 2016000 MHZ_TO_MBPS(1804, 8) >;
			};
		};

		cpu4_computemon: qcom,cpu4-computemon {
			compatible = "qcom,arm-compute-mon";
			qcom,cpulist = <&CPU4 &CPU5 &CPU6 &CPU7>;
			qcom,target-dev = <&cpu4_cpu_ddr_latfloor>;
			ddr3-map {
				qcom,ddr-type = <DDR_TYPE_LPDDR3>;
				qcom,core-dev-table =
					<  652800 MHZ_TO_MBPS( 200, 8) >,
					< 1056000 MHZ_TO_MBPS( 451, 8) >,
					< 1401600 MHZ_TO_MBPS( 547, 8) >,
					< 1536000 MHZ_TO_MBPS( 768, 8) >,
					< 2016000 MHZ_TO_MBPS( 931, 8) >;
			};

			ddr4-map {
				qcom,ddr-type = <DDR_TYPE_LPDDR4X>;
				qcom,core-dev-table =
					<  902400 MHZ_TO_MBPS( 300, 8) >,
					< 1056000 MHZ_TO_MBPS( 547, 8) >,
					< 1401680 MHZ_TO_MBPS( 768, 8) >,
					< 1804800 MHZ_TO_MBPS(1017, 8) >,
					< 2016000 MHZ_TO_MBPS(1804, 8) >;
			};
		};
	};

	qcom,msm_gsi {
		compatible = "qcom,msm_gsi";
	};

	qcom,rmnet-ipa {
		compatible = "qcom,rmnet-ipa3";
		qcom,rmnet-ipa-ssr;
		qcom,ipa-platform-type-msm;
		qcom,ipa-advertise-sg-support;
		qcom,ipa-napi-enable;
	};

	ipa_hw: qcom,ipa@0x5800000 {
		compatible = "qcom,ipa";
		reg = <0x5800000 0x34000>,
			<0x5804000 0x28000>;
		reg-names = "ipa-base", "gsi-base";
		interrupts = <0 257 0>, <0 259 0>;
		interrupt-names = "ipa-irq", "gsi-irq";
		qcom,ipa-hw-ver = <16>; /* IPA core version = IPAv4.2 */
		qcom,ipa-hw-mode = <0>;
		qcom,platform-type = <1>; /* MSM platform */
		qcom,ee = <0>;
		qcom,use-ipa-tethering-bridge;
		qcom,modem-cfg-emb-pipe-flt;
		qcom,ipa-wdi2;
		qcom,ipa-wdi2_over_gsi;
		qcom,ipa-endp-delay-wa;
		qcom,ipa-fltrt-not-hashable;
		qcom,use-64-bit-dma-mask;
		qcom,arm-smmu;
		qcom,smmu-fast-map;
		qcom,use-ipa-pm;
		qcom,skip-ieob-mask-wa;
		clocks = <&rpmcc RPM_SMD_IPA_CLK>;
		clock-names = "core_clk";
		qcom,msm-bus,name = "ipa";
		qcom,msm-bus,num-cases = <5>;
		qcom,msm-bus,num-paths = <3>;
		qcom,msm-bus,vectors-KBps =
		/* No vote */
		<MSM_BUS_MASTER_IPA MSM_BUS_SLAVE_EBI_CH0 0 0>,
		<MSM_BUS_MASTER_IPA MSM_BUS_SLAVE_OCIMEM 0 0>,
		<MSM_BUS_MASTER_AMPSS_M0 MSM_BUS_SLAVE_IPA_CFG 0 0>,
		/* SVS2 */
		<MSM_BUS_MASTER_IPA MSM_BUS_SLAVE_EBI_CH0 80000 465000>,
		<MSM_BUS_MASTER_IPA MSM_BUS_SLAVE_OCIMEM 80000 68570>,
		<MSM_BUS_MASTER_AMPSS_M0 MSM_BUS_SLAVE_IPA_CFG 80000 30>,
		/* SVS */
		<MSM_BUS_MASTER_IPA MSM_BUS_SLAVE_EBI_CH0 80000 2000000>,
		<MSM_BUS_MASTER_IPA MSM_BUS_SLAVE_OCIMEM 80000 267461>,
		<MSM_BUS_MASTER_AMPSS_M0 MSM_BUS_SLAVE_IPA_CFG 80000 109890>,
		/* NOMINAL */
		<MSM_BUS_MASTER_IPA MSM_BUS_SLAVE_EBI_CH0  206000 4000000>,
		<MSM_BUS_MASTER_IPA MSM_BUS_SLAVE_OCIMEM 206000 712961>,
		<MSM_BUS_MASTER_AMPSS_M0 MSM_BUS_SLAVE_IPA_CFG 206000 491520>,
		/* TURBO */
		<MSM_BUS_MASTER_IPA MSM_BUS_SLAVE_EBI_CH0 206000 5598900>,
		<MSM_BUS_MASTER_IPA MSM_BUS_SLAVE_OCIMEM 206000 1436481>,
		<MSM_BUS_MASTER_AMPSS_M0 MSM_BUS_SLAVE_IPA_CFG 206000 491520>;
		qcom,bus-vector-names =
				"MIN", "SVS2", "SVS", "NOMINAL", "TURBO";
		qcom,throughput-threshold = <310 600 1000>;
		qcom,scaling-exceptions = <>;

		/* smp2p information */
		qcom,smp2p_map_ipa_1_out {
			compatible = "qcom,smp2p-map-ipa-1-out";
		qcom,smem-states = <&smp2p_ipa_1_out 0>;
			qcom,smem-state-names = "ipa-smp2p-out";
		};

		qcom,smp2p_map_ipa_1_in {
			compatible = "qcom,smp2p-map-ipa-1-in";
			interrupts-extended = <&smp2p_ipa_1_in 0 0>;
			interrupt-names = "ipa-smp2p-in";
		};
	};

	ipa_smmu_ap: ipa_smmu_ap {
		compatible = "qcom,ipa-smmu-ap-cb";
		iommus = <&apps_smmu 0x0140 0x0>;
		qcom,iommu-dma-addr-pool = <0x10000000 0x30000000>;
		qcom,iommu-dma = "bypass";
		/* modem tables in IMEM */
		qcom,additional-mapping = <0x0c123000 0x0c123000 0x2000>;
	};

	ipa_smmu_wlan: ipa_smmu_wlan {
		compatible = "qcom,ipa-smmu-wlan-cb";
		iommus = <&apps_smmu 0x0141 0x0>;
		qcom,iommu-dma = "bypass";
		/* ipa-uc ram */
		qcom,additional-mapping = <0x5860000 0x5860000 0x80000>;
	};

	ipa_smmu_uc: ipa_smmu_uc {
		compatible = "qcom,ipa-smmu-uc-cb";
		iommus = <&apps_smmu 0x0142 0x0>;
		qcom,iommu-dma = "bypass";
		qcom,iommu-dma-addr-pool = <0x40400000 0x1fc00000>;
	};

	qcom,ipa_fws {
		compatible = "qcom,pil-tz-generic";
		qcom,pas-id = <0xf>;
		qcom,firmware-name = "ipa_fws";
		qcom,pil-force-shutdown;
		memory-region = <&pil_ipa_fw_mem>;
	};

	qcom,demux {
		compatible = "qcom,demux";
	};
};

#include "bengal-gdsc.dtsi"
#include "bengal-usb.dtsi"
#include "bengal-ion.dtsi"
#include "bengal-coresight.dtsi"
#include "bengal-bus.dtsi"
#include "bengal-vidc.dtsi"
#include "pmi632.dtsi"
#include "pm6125.dtsi"

&gcc_camss_top_gdsc {
	status = "ok";
};

&gcc_ufs_phy_gdsc {
	status = "ok";
};

&gcc_usb30_prim_gdsc {
	status = "ok";
};

&gcc_vcodec0_gdsc {
	qcom,support-hw-trigger;
	status = "ok";
};

&gcc_venus_gdsc {
	status = "ok";
};

&hlos1_vote_turing_mmu_tbu1_gdsc {
	status = "ok";
};

&hlos1_vote_turing_mmu_tbu0_gdsc {
	status = "ok";
};

&hlos1_vote_mm_snoc_mmu_tbu_rt_gdsc {
	status = "ok";
};

&hlos1_vote_mm_snoc_mmu_tbu_nrt_gdsc {
	status = "ok";
};

&mdss_core_gdsc {
	qcom,support-hw-trigger;
	status = "ok";
};

&gpu_cx_gdsc {
	parent-supply = <&VDD_CX_LEVEL>;
	status = "ok";
};

&gpu_gx_gdsc {
	parent-supply = <&VDD_CX_LEVEL>;
	status = "ok";
};

#include "msm-arm-smmu-bengal.dtsi"
#include "pm6125-rpm-regulator.dtsi"
#include "bengal-regulator.dtsi"
#include "bengal-pm.dtsi"
#include "bengal-pinctrl.dtsi"
#include "bengal-qupv3.dtsi"
#include "bengal-gpu.dtsi"
#include "bengal-audio.dtsi"
#include "bengal-sde-pll.dtsi"
#include "bengal-sde.dtsi"

&qupv3_se1_i2c {
	status = "ok";
	#include "pm8008.dtsi"
};

&pm8008_8 {
	/* PM8008 IRQ STAT */
	interrupt-parent = <&tlmm>;
	interrupts = <25 IRQ_TYPE_EDGE_RISING>;

	pinctrl-names = "default";
	pinctrl-0 = <&pm8008_active &pm8008_interrupt>;
};

&pm8008_regulators {
	vdd_l1_l2-supply = <&S6A>;
};

&L1P {
	regulator-max-microvolt = <1200000>;
	qcom,min-dropout-voltage = <100000>;
};

&L2P {
	regulator-max-microvolt = <1056000>;
	qcom,min-dropout-voltage = <100000>;
};

&L3P {
	regulator-min-microvolt = <2800000>;
	regulator-max-microvolt = <2800000>;
};

&L4P {
	regulator-min-microvolt = <2800000>;
	regulator-max-microvolt = <2800000>;
};

&L5P {
	regulator-min-microvolt = <2800000>;
	regulator-max-microvolt = <2800000>;
};

&L6P {
	regulator-min-microvolt = <2800000>;
	regulator-max-microvolt = <2800000>;
};

&L7P {
	regulator-min-microvolt = <1800000>;
	regulator-max-microvolt = <1800000>;
};

&qupv3_se4_2uart {
	status = "ok";
};

&qupv3_se3_4uart {
	status = "ok";
};

&pm6125_vadc {
	#address-cells = <1>;
	#size-cells = <0>;
	pinctrl-names = "default";
	pinctrl-0 = <&camera_therm_default &emmc_therm_default>;

	pa_therm0 {
		reg = <ADC_AMUX_THM1_PU2>;
		label = "pa_therm0";
		qcom,ratiometric;
		qcom,hw-settle-time = <200>;
		qcom,pre-scaling = <1 1>;
	};

	quiet_therm {
		reg = <ADC_AMUX_THM2_PU2>;
		label = "quiet_therm";
		qcom,ratiometric;
		qcom,hw-settle-time = <200>;
		qcom,pre-scaling = <1 1>;
	};

	camera_flash_therm {
		reg = <ADC_GPIO1_PU2>;
		label = "camera_flash_therm";
		qcom,ratiometric;
		qcom,hw-settle-time = <200>;
		qcom,pre-scaling = <1 1>;
	};

	emmc_ufs_therm {
		reg = <ADC_GPIO2_PU2>;
		label = "emmc_ufs_therm";
		qcom,ratiometric;
		qcom,hw-settle-time = <200>;
		qcom,pre-scaling = <1 1>;
	};
};

&pm6125_gpios {
	camera_therm {
		camera_therm_default: camera_therm_default {
			pins = "gpio3";
			bias-high-impedance;
		};
	};

	emmc_therm {
		emmc_therm_default: emmc_therm_default {
			pins = "gpio4";
			bias-high-impedance;
		};
	};

};

&spmi_bus {
	qcom,pm6125@0 {
		pm6125_adc_tm_iio: adc_tm@3400 {
			compatible = "qcom,adc-tm5-iio";
			reg = <0x3400 0x100>;
			#thermal-sensor-cells = <1>;
			#address-cells = <1>;
			#size-cells = <0>;
			io-channels = <&pm6125_vadc ADC_GPIO1_PU2>,
					<&pm6125_vadc ADC_GPIO2_PU2>;

			camera_flash_therm {
				reg = <ADC_GPIO1_PU2>;
				qcom,ratiometric;
				qcom,hw-settle-time = <200>;
			};

			emmc_ufs_therm {
				reg = <ADC_GPIO2_PU2>;
				qcom,ratiometric;
				qcom,hw-settle-time = <200>;
			};
		};
	};
};

&pm6125_adc_tm {
	#address-cells = <1>;
	#size-cells = <0>;
	io-channels = <&pm6125_vadc ADC_AMUX_THM1_PU2>,
			<&pm6125_vadc ADC_AMUX_THM2_PU2>,
			<&pm6125_vadc ADC_XO_THERM_PU2>;

	/* Channel nodes */
	pa_therm0 {
		reg = <ADC_AMUX_THM1_PU2>;
		qcom,ratiometric;
		qcom,hw-settle-time = <200>;
	};

	quiet_therm {
		reg = <ADC_AMUX_THM2_PU2>;
		qcom,ratiometric;
		qcom,hw-settle-time = <200>;
	};

	xo_therm {
		reg = <ADC_XO_THERM_PU2>;
		qcom,ratiometric;
		qcom,hw-settle-time = <200>;
	};
};

&pmi632_vadc {
	#address-cells = <1>;
	#size-cells = <0>;
	pinctrl-names = "default";
	pinctrl-0 = <&conn_therm_default &skin_therm_default>;

	conn_therm {
		reg = <ADC_GPIO1_PU2>;
		label = "conn_therm";
		qcom,ratiometric;
		qcom,hw-settle-time = <200>;
		qcom,pre-scaling = <1 1>;
	};

	skin_therm {
		reg = <ADC_GPIO2_PU2>;
		label = "skin_therm";
		qcom,ratiometric;
		qcom,hw-settle-time = <200>;
		qcom,pre-scaling = <1 1>;
	};
};

&pmi632_gpios {
	conn_therm {
		conn_therm_default: conn_therm_default {
			pins = "gpio1";
			bias-high-impedance;
		};
	};

	skin_therm {
		skin_therm_default: skin_therm_default {
			pins = "gpio3";
			bias-high-impedance;
		};
	};

};

&pmi632_adc_tm {
	#address-cells = <1>;
	#size-cells = <0>;
	io-channels = <&pmi632_vadc ADC_GPIO2_PU2>;

	/* Channel nodes */
	skin_therm {
		reg = <ADC_GPIO2_PU2>;
		qcom,ratiometric;
		qcom,hw-settle-time = <200>;
	};
};

&msm_vidc {
	qcom,cx-ipeak-data = <&cx_ipeak_lm 6>;
	qcom,clock-freq-threshold = <300000000>;
};

#include "bengal-thermal.dtsi"
#include "camera/bengal-camera.dtsi"
#include "msm-rdbg.dtsi"
